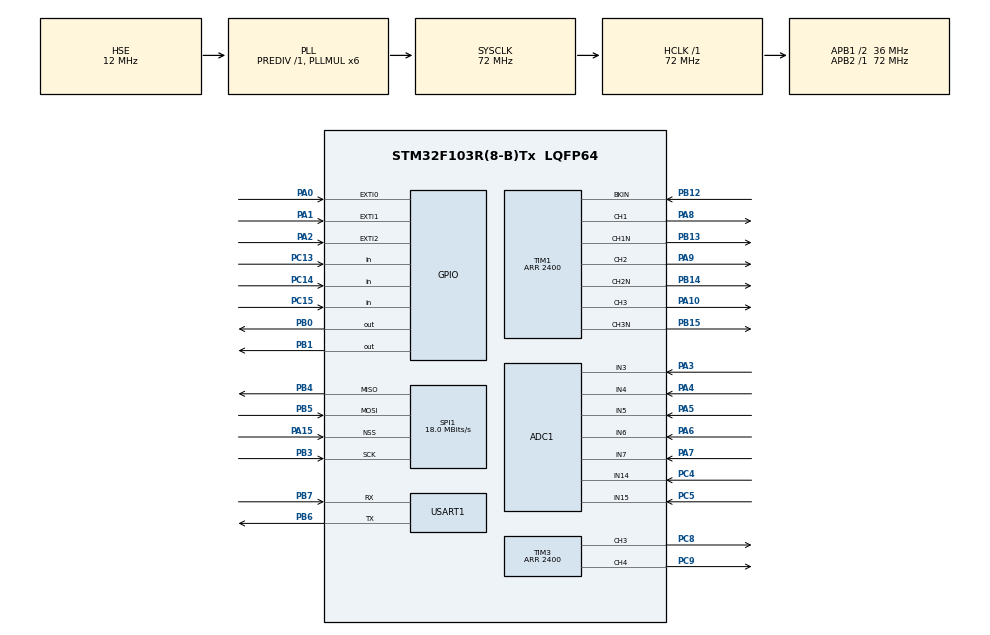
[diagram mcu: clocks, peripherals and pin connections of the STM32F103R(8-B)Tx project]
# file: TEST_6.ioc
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ADC1.Channel-0\#ChannelRegularConversion=ADC_CHANNEL_4
ADC1.Channel-1\#ChannelRegularConversion=ADC_CHANNEL_6
ADC1.Channel-2\#ChannelRegularConversion=ADC_CHANNEL_14
ADC1.ContinuousConvMode=ENABLE
ADC1.DataAlign=ADC_DATAALIGN_RIGHT
ADC1.DiscontinuousConvMode=DISABLE
ADC1.EnableAnalogWatchDog=false
ADC1.EnableRegularConversion=ENABLE
ADC1.ExternalTrigConvEdgeChoice=NONE
ADC1.InjNumberOfConversion=0
ADC1.NbrOfConversion=3
ADC1.NbrOfConversionFlag=1
ADC1.Rank-0\#ChannelRegularConversion=1
ADC1.Rank-1\#ChannelRegularConversion=2
ADC1.Rank-2\#ChannelRegularConversion=3
ADC1.SamplingTime-0\#ChannelRegularConversion=ADC_SAMPLETIME_28CYCLES_5
ADC1.SamplingTime-1\#ChannelRegularConversion=ADC_SAMPLETIME_28CYCLES_5
ADC1.SamplingTime-2\#ChannelRegularConversion=ADC_SAMPLETIME_28CYCLES_5
ADC1.ScanConvMode=ADC_SCAN_ENABLE
ADC1.master=1
Dma.ADC1.0.Direction=DMA_PERIPH_TO_MEMORY
Dma.ADC1.0.Instance=DMA1_Channel1
Dma.ADC1.0.MemDataAlignment=DMA_MDATAALIGN_HALFWORD
Dma.ADC1.0.MemInc=DMA_MINC_ENABLE
Dma.ADC1.0.Mode=DMA_CIRCULAR
Dma.ADC1.0.PeriphDataAlignment=DMA_PDATAALIGN_HALFWORD
Dma.ADC1.0.PeriphInc=DMA_PINC_DISABLE
Dma.ADC1.0.Priority=DMA_PRIORITY_VERY_HIGH
Dma.Request0=ADC1
Dma.Request1=SPI1_RX
Dma.SPI1_RX.1.Direction=DMA_PERIPH_TO_MEMORY
Dma.SPI1_RX.1.Instance=DMA1_Channel2
Dma.SPI1_RX.1.MemDataAlignment=DMA_MDATAALIGN_BYTE
Dma.SPI1_RX.1.MemInc=DMA_MINC_ENABLE
Dma.SPI1_RX.1.Mode=DMA_CIRCULAR
Dma.SPI1_RX.1.PeriphDataAlignment=DMA_PDATAALIGN_BYTE
Dma.SPI1_RX.1.PeriphInc=DMA_PINC_DISABLE
Dma.SPI1_RX.1.Priority=DMA_PRIORITY_LOW
Mcu.Family=STM32F1
Mcu.Name=STM32F103R(8-B)Tx
Mcu.Package=LQFP64
NVIC.DMA1_Channel1_IRQn=true\:4\:0\:true
NVIC.DMA1_Channel2_IRQn=true\:0\:0\:false
NVIC.EXTI0_IRQn=true\:1\:0\:true
NVIC.EXTI1_IRQn=true\:1\:0\:true
NVIC.EXTI2_IRQn=true\:1\:0\:true
NVIC.PriorityGroup=NVIC_PRIORITYGROUP_4
NVIC.SPI1_IRQn=true\:0\:0\:false
NVIC.TIM1_BRK_IRQn=true\:0\:0\:false
NVIC.TIM2_IRQn=true\:5\:0\:true
NVIC.TIM4_IRQn=true\:2\:0\:true
PA0-WKUP.GPIO_ModeDefaultEXTI=GPIO_MODE_IT_RISING_FALLING
PA0-WKUP.GPIO_PuPd=GPIO_NOPULL
PA0-WKUP.Signal=GPXTI0
PA1.GPIO_ModeDefaultEXTI=GPIO_MODE_IT_RISING_FALLING
PA1.GPIO_PuPd=GPIO_NOPULL
PA1.Signal=GPXTI1
PA10.Signal=S_TIM1_CH3
PA13.Mode=Serial_Wire
PA13.Signal=SYS_JTMS-SWDIO
PA14.Mode=Serial_Wire
PA14.Signal=SYS_JTCK-SWCLK
PA15.Mode=NSS_Signal_Hard_Input
PA15.Signal=SPI1_NSS
PA2.GPIO_ModeDefaultEXTI=GPIO_MODE_IT_RISING_FALLING
PA2.GPIO_PuPd=GPIO_NOPULL
PA2.Signal=GPXTI2
PA3.Signal=ADCx_IN3
PA4.Signal=ADCx_IN4
PA5.Signal=ADCx_IN5
PA6.Signal=ADCx_IN6
PA7.Signal=ADCx_IN7
PA8.Signal=S_TIM1_CH1
PA9.Signal=S_TIM1_CH2
PB0.Signal=GPIO_Output
PB1.GPIO_ModeDefaultOutputPP=GPIO_MODE_OUTPUT_PP
PB1.GPIO_Speed=GPIO_SPEED_HIGH
PB1.Signal=GPIO_Output
PB12.Mode=Activate-Break-Input
PB12.Signal=TIM1_BKIN
PB13.Mode=PWM Generation1 CH1 CH1N
PB13.Signal=TIM1_CH1N
PB14.Mode=PWM Generation2 CH2 CH2N
PB14.Signal=TIM1_CH2N
PB15.Mode=PWM Generation3 CH3 CH3N
PB15.Signal=TIM1_CH3N
PB3.Mode=Full_Duplex_Slave
PB3.Signal=SPI1_SCK
PB4.Mode=Full_Duplex_Slave
PB4.Signal=SPI1_MISO
PB5.Mode=Full_Duplex_Slave
PB5.Signal=SPI1_MOSI
PB6.Mode=Asynchronous
PB6.Signal=USART1_TX
PB7.Mode=Asynchronous
PB7.Signal=USART1_RX
PC13-TAMPER-RTC.GPIO_Mode=GPIO_MODE_INPUT
PC13-TAMPER-RTC.GPIO_PuPd=GPIO_PULLUP
PC13-TAMPER-RTC.Signal=GPIO_Input
PC14-OSC32_IN.GPIO_Mode=GPIO_MODE_INPUT
PC14-OSC32_IN.GPIO_PuPd=GPIO_PULLUP
PC14-OSC32_IN.Signal=GPIO_Input
PC15-OSC32_OUT.GPIO_Mode=GPIO_MODE_INPUT
PC15-OSC32_OUT.GPIO_PuPd=GPIO_PULLUP
PC15-OSC32_OUT.Signal=GPIO_Input
PC4.Signal=ADCx_IN14
PC5.Signal=ADCx_IN15
PC8.Signal=S_TIM3_CH3
PC9.Signal=S_TIM3_CH4
PD0-OSC_IN.Mode=HSE-External-Oscillator
PD0-OSC_IN.Signal=RCC_OSC_IN
PD1-OSC_OUT.Mode=HSE-External-Oscillator
PD1-OSC_OUT.Signal=RCC_OSC_OUT
ProjectManager.HeapSize=0x400
ProjectManager.StackSize=0x200
ProjectManager.TargetToolchain=SW4STM32
RCC.ADCPresc=RCC_ADCPCLK2_DIV6
RCC.AHBFreq_Value=72000000
RCC.APB1CLKDivider=RCC_HCLK_DIV2
RCC.APB1Freq_Value=36000000
RCC.APB1TimFreq_Value=72000000
RCC.APB2Freq_Value=72000000
RCC.APB2TimFreq_Value=72000000
RCC.HCLKFreq_Value=72000000
RCC.HSE_VALUE=12000000
RCC.HSIState=RCC_HSI_ON
RCC.PLLMUL=RCC_PLL_MUL6
RCC.PLLSourceVirtual=RCC_PLLSOURCE_HSE
RCC.SYSCLKFreq_VALUE=72000000
RCC.SYSCLKSource=RCC_SYSCLKSOURCE_PLLCLK
RCC.USBFreq_Value=72000000
SH.ADCx_IN14.0=ADC1_IN14,IN14
SH.ADCx_IN15.0=ADC1_IN15,IN15
SH.ADCx_IN3.0=ADC1_IN3,IN3
SH.ADCx_IN4.0=ADC1_IN4,IN4
SH.ADCx_IN5.0=ADC1_IN5,IN5
SH.ADCx_IN6.0=ADC1_IN6,IN6
SH.ADCx_IN7.0=ADC1_IN7,IN7
SH.S_TIM1_CH1.0=TIM1_CH1,PWM Generation1 CH1 CH1N
SH.S_TIM1_CH2.0=TIM1_CH2,PWM Generation2 CH2 CH2N
SH.S_TIM1_CH3.0=TIM1_CH3,PWM Generation3 CH3 CH3N
SH.S_TIM3_CH3.0=TIM3_CH3,PWM Generation3 CH3
SH.S_TIM3_CH4.0=TIM3_CH4,PWM Generation4 CH4
SPI1.BaudRatePrescaler=SPI_BAUDRATEPRESCALER_4
SPI1.CLKPhase=SPI_PHASE_2EDGE
SPI1.CalculateBaudRate=18.0 MBits/s
SPI1.VirtualNSS=VM_NSSHARD
SPI1.VirtualType=VM_SLAVE
TIM1.AutomaticOutput=TIM_AUTOMATICOUTPUT_DISABLE
TIM1.BreakPolarity=TIM_BREAKPOLARITY_LOW
TIM1.BreakState=TIM_BREAK_ENABLE
TIM1.Channel-PWM\ Generation2\ CH2\ CH2N=TIM_CHANNEL_2
TIM1.Channel-PWM\ Generation3\ CH3\ CH3N=TIM_CHANNEL_3
TIM1.CounterMode=TIM_COUNTERMODE_CENTERALIGNED3
TIM1.DeadTime=0
TIM1.OCFastMode_PWM-PWM\ Generation1\ CH1\ CH1N=TIM_OCFAST_ENABLE
TIM1.OCFastMode_PWM-PWM\ Generation2\ CH2\ CH2N=TIM_OCFAST_ENABLE
TIM1.OCFastMode_PWM-PWM\ Generation3\ CH3\ CH3N=TIM_OCFAST_ENABLE
TIM1.OCIdleState_1=TIM_OCIDLESTATE_SET
TIM1.OCIdleState_2=TIM_OCIDLESTATE_SET
TIM1.OCIdleState_3=TIM_OCIDLESTATE_SET
TIM1.OCNIdleState_1=TIM_OCNIDLESTATE_SET
TIM1.OCNIdleState_2=TIM_OCNIDLESTATE_SET
TIM1.OCNIdleState_3=TIM_OCNIDLESTATE_SET
TIM1.OCNPolarity_1=TIM_OCNPOLARITY_HIGH
TIM1.OCNPolarity_2=TIM_OCNPOLARITY_HIGH
TIM1.OCNPolarity_3=TIM_OCNPOLARITY_HIGH
TIM1.OCPolarity_1=TIM_OCPOLARITY_HIGH
TIM1.OCPolarity_2=TIM_OCPOLARITY_HIGH
TIM1.OCPolarity_3=TIM_OCPOLARITY_HIGH
TIM1.OffStateIDLEMode=TIM_OSSI_ENABLE
TIM1.OffStateRunMode=TIM_OSSR_ENABLE
TIM1.Period=2400
TIM2.Period=65535
TIM2.Prescaler=600
TIM3.Channel-PWM\ Generation3\ CH3=TIM_CHANNEL_3
TIM3.Channel-PWM\ Generation4\ CH4=TIM_CHANNEL_4
TIM3.OCFastMode_PWM-PWM\ Generation3\ CH3=TIM_OCFAST_ENABLE
TIM3.OCFastMode_PWM-PWM\ Generation4\ CH4=TIM_OCFAST_ENABLE
TIM3.Period=2400
TIM4.Period=4800
VP_TIM1_VS_ClockSourceINT.Mode=Internal
VP_TIM2_VS_ClockSourceINT.Mode=Internal
VP_TIM4_VS_ClockSourceINT.Mode=Internal
board=TEST_6

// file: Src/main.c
/**
  ******************************************************************************
  * File Name          : main.c
  * Description        : Main program body
  ******************************************************************************
  *
  * COPYRIGHT(c) 2016 STMicroelectronics
  *
  * Redistribution and use in source and binary forms, with or without modification,
  * are permitted provided that the following conditions are met:
  *   1. Redistributions of source code must retain the above copyright notice,
  *      this list of conditions and the following disclaimer.
  *   2. Redistributions in binary form must reproduce the above copyright notice,
  *      this list of conditions and the following disclaimer in the documentation
  *      and/or other materials provided with the distribution.
  *   3. Neither the name of STMicroelectronics nor the names of its contributors
  *      may be used to endorse or promote products derived from this software
  *      without specific prior written permission.
  *
  * THIS SOFTWARE IS PROVIDED BY THE COPYRIGHT HOLDERS AND CONTRIBUTORS "AS IS"
  * AND ANY EXPRESS OR IMPLIED WARRANTIES, INCLUDING, BUT NOT LIMITED TO, THE
  * IMPLIED WARRANTIES OF MERCHANTABILITY AND FITNESS FOR A PARTICULAR PURPOSE ARE
  * DISCLAIMED. IN NO EVENT SHALL THE COPYRIGHT HOLDER OR CONTRIBUTORS BE LIABLE
  * FOR ANY DIRECT, INDIRECT, INCIDENTAL, SPECIAL, EXEMPLARY, OR CONSEQUENTIAL
  * DAMAGES (INCLUDING, BUT NOT LIMITED TO, PROCUREMENT OF SUBSTITUTE GOODS OR
  * SERVICES; LOSS OF USE, DATA, OR PROFITS; OR BUSINESS INTERRUPTION) HOWEVER
  * CAUSED AND ON ANY THEORY OF LIABILITY, WHETHER IN CONTRACT, STRICT LIABILITY,
  * OR TORT (INCLUDING NEGLIGENCE OR OTHERWISE) ARISING IN ANY WAY OUT OF THE USE
  * OF THIS SOFTWARE, EVEN IF ADVISED OF THE POSSIBILITY OF SUCH DAMAGE.
  *
  ******************************************************************************
  */
#include "stm32f1xx_hal.h"
#include "adc.h"
#include "dma.h"
#include "spi.h"
#include "tim.h"
#include "usart.h"
#include "gpio.h"

/* USER CODE BEGIN Includes */
int32_t NO_OF;

uint16_t const SVM_TABLE[4800]={
	2078,2080,2081,2083,2084,2086,2087,2089,2090,2092,
	2093,2095,2097,2098,2100,2101,2103,2104,2106,2107,2109,2110,2112,2113,
	2115,2116,2118,2119,2121,2122,2123,2125,2126,2128,2129,2131,2132,
	2134,2135,2136,2138,2139,2141,2142,2144,2145,2146,2148,2149,2151,2152,
	2153,2155,2156,2158,2159,2160,2162,2163,2164,2166,2167,2168,2170,2171,
	2172,2174,2175,2176,2178,2179,2180,2182,2183,2184,2186,2187,2188,
	2189,2191,2192,2193,2195,2196,2197,2198,2200,2201,2202,2203,2205,2206,
	2207,2208,2210,2211,2212,2213,2214,2216,2217,2218,2219,2220,2222,
	2223,2224,2225,2226,2227,2229,2230,2231,2232,2233,2234,2236,2237,2238,
	2239,2240,2241,2242,2243,2245,2246,2247,2248,2249,2250,2251,2252,2253,
	2254,2255,2257,2258,2259,2260,2261,2262,2263,2264,2265,2266,2267,
	2268,2269,2270,2271,2272,2273,2274,2275,2276,2277,2278,2279,2280,2281,
	2282,2283,2284,2285,2286,2287,2288,2289,2290,2291,2292,2292,2293,
	2294,2295,2296,2297,2298,2299,2300,2301,2302,2302,2303,2304,2305,2306,
	2307,2308,2309,2309,2310,2311,2312,2313,2314,2314,2315,2316,2317,2318,
	2319,2319,2320,2321,2322,2323,2323,2324,2325,2326,2326,2327,2328,
	2329,2329,2330,2331,2332,2332,2333,2334,2335,2335,2336,2337,2338,2338,
	2339,2340,2340,2341,2342,2342,2343,2344,2344,2345,2346,2346,2347,
	2348,2348,2349,2350,2350,2351,2352,2352,2353,2353,2354,2355,2355,2356,
	2356,2357,2358,2358,2359,2359,2360,2360,2361,2362,2362,2363,2363,2364,
	2364,2365,2365,2366,2366,2367,2367,2368,2368,2369,2369,2370,2370,
	2371,2371,2372,2372,2373,2373,2374,2374,2375,2375,2376,2376,2376,2377,
	2377,2378,2378,2379,2379,2379,2380,2380,2381,2381,2381,2382,2382,
	2382,2383,2383,2384,2384,2384,2385,2385,2385,2386,2386,2386,2387,2387,
	2387,2388,2388,2388,2389,2389,2389,2389,2390,2390,2390,2391,2391,2391,
	2391,2392,2392,2392,2392,2393,2393,2393,2393,2394,2394,2394,2394,
	2394,2395,2395,2395,2395,2395,2396,2396,2396,2396,2396,2396,2397,2397,
	2397,2397,2397,2397,2397,2398,2398,2398,2398,2398,2398,2398,2398,
	2398,2399,2399,2399,2399,2399,2399,2399,2399,2399,2399,2399,2399,2399,
	2399,2399,2399,2399,2399,2399,2399,2399,2399,2399,2399,2399,2399,2399,
	2399,2399,2399,2399,2399,2399,2399,2399,2399,2399,2399,2399,2399,
	2399,2399,2399,2399,2399,2398,2398,2398,2398,2398,2398,2398,2398,2398,
	2397,2397,2397,2397,2397,2397,2397,2396,2396,2396,2396,2396,2396,
	2395,2395,2395,2395,2395,2394,2394,2394,2394,2394,2393,2393,2393,2393,
	2392,2392,2392,2392,2391,2391,2391,2391,2390,2390,2390,2389,2389,2389,
	2389,2388,2388,2388,2387,2387,2387,2386,2386,2386,2385,2385,2385,
	2384,2384,2384,2383,2383,2382,2382,2382,2381,2381,2381,2380,2380,2379,
	2379,2379,2378,2378,2377,2377,2376,2376,2376,2375,2375,2374,2374,
	2373,2373,2372,2372,2371,2371,2370,2370,2369,2369,2368,2368,2367,2367,
	2366,2366,2365,2365,2364,2364,2363,2363,2362,2362,2361,2360,2360,2359,
	2359,2358,2358,2357,2356,2356,2355,2355,2354,2353,2353,2352,2352,
	2351,2350,2350,2349,2348,2348,2347,2346,2346,2345,2344,2344,2343,2342,
	2342,2341,2340,2340,2339,2338,2338,2337,2336,2335,2335,2334,2333,
	2332,2332,2331,2330,2329,2329,2328,2327,2326,2326,2325,2324,2323,2323,
	2322,2321,2320,2319,2319,2318,2317,2316,2315,2314,2314,2313,2312,2311,
	2310,2309,2309,2308,2307,2306,2305,2304,2303,2302,2302,2301,2300,
	2299,2298,2297,2296,2295,2294,2293,2292,2292,2291,2290,2289,2288,2287,
	2286,2285,2284,2283,2282,2281,2280,2279,2278,2277,2276,2275,2274,
	2273,2272,2271,2270,2269,2268,2267,2266,2265,2264,2263,2262,2261,2260,
	2259,2258,2257,2255,2254,2253,2252,2251,2250,2249,2248,2247,2246,2245,
	2243,2242,2241,2240,2239,2238,2237,2236,2234,2233,2232,2231,2230,
	2229,2227,2226,2225,2224,2223,2222,2220,2219,2218,2217,2216,2214,2213,
	2212,2211,2210,2208,2207,2206,2205,2203,2202,2201,2200,2198,2197,
	2196,2195,2193,2192,2191,2189,2188,2187,2186,2184,2183,2182,2180,2179,
	2178,2176,2175,2174,2172,2171,2170,2168,2167,2166,2164,2163,2162,2160,
	2159,2158,2156,2155,2153,2152,2151,2149,2148,2146,2145,2144,2142,
	2141,2139,2138,2136,2135,2134,2132,2131,2129,2128,2126,2125,2123,2122,
	2121,2119,2118,2116,2115,2113,2112,2110,2109,2107,2106,2104,2103,
	2101,2100,2098,2097,2095,2093,2092,2090,2089,2087,2086,2084,2083,2081,
	2080,2078,2076,2075,2073,2072,2070,2068,2067,2065,2064,2062,2060,2059,
	2057,2056,2054,2052,2051,2049,2047,2046,2044,2043,2041,2039,2038,
	2036,2034,2033,2031,2029,2028,2026,2024,2023,2021,2019,2017,2016,2014,
	2012,2011,2009,2007,2005,2004,2002,2000,1999,1997,1995,1993,1992,
	1990,1988,1986,1984,1983,1981,1979,1977,1976,1974,1972,1970,1968,1967,
	1965,1963,1961,1959,1958,1956,1954,1952,1950,1949,1947,1945,1943,1941,
	1939,1937,1936,1934,1932,1930,1928,1926,1924,1923,1921,1919,1917,
	1915,1913,1911,1909,1907,1905,1904,1902,1900,1898,1896,1894,1892,1890,
	1888,1886,1884,1882,1880,1878,1876,1874,1873,1871,1869,1867,1865,
	1863,1861,1859,1857,1855,1853,1851,1849,1847,1845,1843,1841,1839,1837,
	1835,1833,1831,1829,1827,1824,1822,1820,1818,1816,1814,1812,1810,1808,
	1806,1804,1802,1800,1798,1796,1794,1791,1789,1787,1785,1783,1781,
	1779,1777,1775,1772,1770,1768,1766,1764,1762,1760,1758,1755,1753,1751,
	1749,1747,1745,1743,1740,1738,1736,1734,1732,1730,1727,1725,1723,
	1721,1719,1716,1714,1712,1710,1708,1705,1703,1701,1699,1697,1694,1692,
	1690,1688,1685,1683,1681,1679,1676,1674,1672,1670,1667,1665,1663,1661,
	1658,1656,1654,1652,1649,1647,1645,1642,1640,1638,1636,1633,1631,
	1629,1626,1624,1622,1619,1617,1615,1612,1610,1608,1605,1603,1601,1598,
	1596,1594,1591,1589,1587,1584,1582,1580,1577,1575,1572,1570,1568,
	1565,1563,1561,1558,1556,1553,1551,1549,1546,1544,1541,1539,1537,1534,
	1532,1529,1527,1524,1522,1520,1517,1515,1512,1510,1507,1505,1503,1500,
	1498,1495,1493,1490,1488,1485,1483,1480,1478,1475,1473,1470,1468,
	1466,1463,1461,1458,1456,1453,1451,1448,1446,1443,1441,1438,1435,1433,
	1430,1428,1425,1423,1420,1418,1415,1413,1410,1408,1405,1403,1400,
	1397,1395,1392,1390,1387,1385,1382,1380,1377,1374,1372,1369,1367,1364,
	1361,1359,1356,1354,1351,1349,1346,1343,1341,1338,1335,1333,1330,1328,
	1325,1322,1320,1317,1315,1312,1309,1307,1304,1301,1299,1296,1293,
	1291,1288,1285,1283,1280,1278,1275,1272,1270,1267,1264,1262,1259,1256,
	1253,1251,1248,1245,1243,1240,1237,1235,1232,1229,1227,1224,1221,
	1218,1216,1213,1210,1208,1205,1202,1199,1197,1194,1191,1189,1186,1183,
	1180,1178,1175,1172,1169,1167,1164,1161,1158,1156,1153,1150,1147,1145,
	1142,1139,1136,1134,1131,1128,1125,1123,1120,1117,1114,1111,1109,
	1106,1103,1100,1097,1095,1092,1089,1086,1083,1081,1078,1075,1072,1069,
	1067,1064,1061,1058,1055,1053,1050,1047,1044,1041,1038,1036,1033,
	1030,1027,1024,1021,1019,1016,1013,1010,1007,1004,1001,999,996,993,990,
	987,984,981,979,976,973,970,967,964,961,958,956,953,950,947,944,941,
	938,935,932,930,927,924,921,918,915,912,909,906,903,900,898,895,892,
	889,886,883,880,877,874,871,868,865,863,860,857,854,851,848,845,842,
	839,836,833,830,827,824,821,818,815,812,810,807,804,801,798,795,792,
	789,786,783,780,777,774,771,768,765,762,759,756,753,750,747,744,741,
	738,735,732,729,726,723,720,717,714,711,708,705,702,699,696,693,690,
	687,684,681,678,675,672,669,666,663,660,657,654,651,648,645,642,639,
	636,633,630,627,624,621,618,615,612,609,605,602,599,596,593,590,587,
	584,581,578,575,572,569,566,563,560,557,554,551,548,544,541,538,535,
	532,529,526,523,520,517,514,511,508,505,502,498,495,492,489,486,483,
	480,477,474,471,468,465,462,458,455,452,449,446,443,440,437,434,431,
	428,425,421,418,415,412,409,406,403,400,397,394,390,387,384,381,378,
	375,372,369,366,363,359,356,353,350,347,344,341,338,335,331,328,325,
	322,319,316,313,310,307,303,300,297,294,291,288,285,282,278,275,272,
	269,266,263,260,257,253,250,247,244,241,238,235,232,228,225,222,219,
	216,213,210,207,203,200,197,194,191,188,185,182,178,175,172,169,166,
	163,160,156,153,150,147,144,141,138,135,131,128,125,122,119,116,113,
	109,106,103,100,97,94,91,87,84,81,78,75,72,69,65,62,59,56,53,50,47,
	43,40,37,34,31,28,25,21,18,15,12,9,6,3,0,0,0,0,0,0,0,0,0,0,0,0,0,0,
	0,0,0,0,0,0,0,0,0,0,0,0,0,0,0,0,0,0,0,0,0,0,0,0,0,0,0,0,0,0,0,0,0,0,
	0,0,0,0,0,0,0,0,0,0,0,0,0,0,0,0,0,0,0,0,0,0,0,0,0,0,0,0,0,0,0,0,0,0,
	0,0,0,0,0,0,0,0,0,0,0,0,0,0,0,0,0,0,0,0,0,0,0,0,0,0,0,0,0,0,0,0,0,0,
	0,0,0,0,0,0,0,0,0,0,0,0,0,0,0,0,0,0,0,0,0,0,0,0,0,0,0,0,0,0,0,0,0,0,
	0,0,0,0,0,0,0,0,0,0,0,0,0,0,0,0,0,0,0,0,0,0,0,0,0,0,0,0,0,0,0,0,0,0,
	0,0,0,0,0,0,0,0,0,0,0,0,0,0,0,0,0,0,0,0,0,0,0,0,0,0,0,0,0,0,0,0,0,0,
	0,0,0,0,0,0,0,0,0,0,0,0,0,0,0,0,0,0,0,0,0,0,0,0,0,0,0,0,0,0,0,0,0,0,
	0,0,0,0,0,0,0,0,0,0,0,0,0,0,0,0,0,0,0,0,0,0,0,0,0,0,0,0,0,0,0,0,0,0,
	0,0,0,0,0,0,0,0,0,0,0,0,0,0,0,0,0,0,0,0,0,0,0,0,0,0,0,0,0,0,0,0,0,0,
	0,0,0,0,0,0,0,0,0,0,0,0,0,0,0,0,0,0,0,0,0,0,0,0,0,0,0,0,0,0,0,0,0,0,
	0,0,0,0,0,0,0,0,0,0,0,0,0,0,0,0,0,0,0,0,0,0,0,0,0,0,0,0,0,0,0,0,0,0,
	0,0,0,0,0,0,0,0,0,0,0,0,0,0,0,0,0,0,0,0,0,0,0,0,0,0,0,0,0,0,0,0,0,0,
	0,0,0,0,0,0,0,0,0,0,0,0,0,0,0,0,0,0,0,0,0,0,0,0,0,0,0,0,0,0,0,0,0,0,
	0,0,0,0,0,0,0,0,0,0,0,0,0,0,0,0,0,0,0,0,0,0,0,0,0,0,0,0,0,0,0,0,0,0,
	0,0,0,0,0,0,0,0,0,0,0,0,0,0,0,0,0,0,0,0,0,0,0,0,0,0,0,0,0,0,0,0,0,0,
	0,0,0,0,0,0,0,0,0,0,0,0,0,0,0,0,0,0,0,0,0,0,0,0,0,0,0,0,0,0,0,0,0,0,
	0,0,0,0,0,0,0,0,0,0,0,0,0,0,0,0,0,0,0,0,0,0,0,0,0,0,0,0,0,0,0,0,0,0,
	0,0,0,0,0,0,0,0,0,0,0,0,0,0,0,0,0,0,0,0,0,0,0,0,0,0,0,0,0,0,0,0,0,0,
	0,0,0,0,0,0,0,0,0,0,0,0,0,0,0,0,0,0,0,0,0,0,0,0,0,0,0,0,0,0,0,0,0,0,
	0,0,0,0,0,0,0,0,0,0,0,0,0,0,0,0,0,0,0,0,0,0,0,0,0,0,0,0,0,0,0,0,0,0,
	0,0,0,0,0,0,0,0,0,0,0,0,0,0,0,0,0,0,0,0,0,0,0,0,0,0,0,0,0,0,0,0,0,0,
	0,0,0,0,0,0,0,0,0,0,0,0,0,0,0,0,0,0,0,0,0,0,0,0,0,0,0,0,0,0,0,0,0,0,
	0,0,0,0,0,0,0,0,0,0,0,0,0,0,0,0,0,0,0,0,0,0,0,0,0,0,0,0,0,0,0,0,0,0,
	0,0,0,0,0,0,0,0,0,0,0,0,0,0,0,0,0,0,0,0,0,0,0,0,0,0,0,0,0,0,0,0,0,0,
	0,0,0,0,0,0,0,0,0,0,0,0,0,0,0,0,0,0,0,0,0,0,0,0,0,0,0,0,0,0,0,0,0,0,
	0,0,0,0,0,0,0,0,0,0,0,0,0,0,0,0,0,0,0,0,0,0,0,0,0,0,0,0,0,0,0,0,0,0,
	0,0,0,0,0,0,0,0,0,0,0,0,0,0,0,0,0,0,0,0,0,0,0,0,0,0,0,0,0,0,0,0,0,0,
	0,0,0,0,0,0,0,0,0,0,0,0,0,0,0,0,0,0,0,0,0,0,0,0,0,0,0,0,0,0,0,0,0,0,
	0,0,0,0,0,0,0,0,0,0,0,0,0,0,0,0,0,0,0,0,0,0,0,0,0,0,0,0,0,0,0,0,0,0,
	0,0,0,0,0,0,0,0,0,0,0,0,0,0,0,0,0,0,0,0,0,0,0,0,0,0,0,0,0,0,0,0,0,0,
	0,0,0,0,0,0,0,0,0,0,0,0,0,0,0,0,0,0,0,0,0,0,0,0,0,0,0,0,0,0,0,0,0,0,
	0,0,0,0,0,0,0,0,0,0,0,0,0,0,0,0,0,0,0,0,0,0,0,0,0,0,0,0,0,0,0,0,0,0,
	0,0,0,0,0,0,0,0,0,0,0,0,0,0,0,0,0,0,0,0,0,0,0,0,0,0,0,0,0,0,0,0,0,0,
	0,0,0,0,0,0,0,0,0,0,0,0,0,0,0,0,0,0,0,0,0,0,0,0,0,0,0,0,0,0,0,0,0,0,
	0,0,0,0,0,0,0,0,0,0,0,0,0,0,0,0,0,0,0,0,0,0,0,0,0,0,0,0,0,0,0,0,0,0,
	0,0,0,0,0,0,0,0,0,0,0,0,0,0,0,0,0,0,0,0,0,0,0,0,0,0,0,0,0,0,0,0,0,0,
	0,0,0,0,0,0,0,0,0,0,0,0,0,0,0,0,0,0,0,0,0,0,0,0,0,0,0,0,0,0,0,0,0,0,
	0,0,0,0,0,0,0,0,0,0,0,0,0,0,0,0,0,0,0,0,0,0,0,0,0,0,0,0,0,0,0,0,0,0,
	0,0,0,0,0,0,0,0,0,0,0,0,0,0,0,0,0,0,0,0,0,0,0,0,0,0,0,0,0,0,0,0,0,0,
	0,0,0,0,0,0,0,0,0,0,0,0,0,0,0,0,0,0,0,0,0,0,0,0,0,0,0,0,0,0,0,0,0,0,
	0,0,0,0,0,0,0,0,0,0,0,0,0,0,0,0,0,0,0,0,0,0,0,0,0,0,0,0,0,0,0,0,0,0,
	0,0,0,0,0,0,0,0,0,0,0,0,0,0,0,0,0,0,0,0,0,0,0,0,0,0,0,0,0,0,0,0,0,0,
	0,0,0,0,0,0,0,0,0,0,0,0,0,0,0,0,0,0,0,0,0,0,0,0,0,0,0,0,0,0,0,0,0,0,
	0,0,0,0,0,0,0,0,0,0,0,0,0,0,0,0,0,0,0,0,0,0,0,0,0,0,0,0,0,0,0,0,0,0,
	0,0,0,0,0,0,0,0,0,0,0,0,0,0,0,0,0,0,0,0,0,0,0,0,0,0,0,0,0,0,0,0,0,0,
	0,0,0,0,0,0,0,0,0,0,0,0,0,0,0,0,0,0,0,0,0,0,0,0,0,0,0,0,0,0,0,0,0,0,
	0,0,0,0,0,0,0,0,0,0,0,0,0,0,0,0,0,0,0,0,0,0,0,3,6,9,12,15,18,21,25,
	28,31,34,37,40,43,47,50,53,56,59,62,65,69,72,75,78,81,84,87,91,94,97,
	100,103,106,109,113,116,119,122,125,128,131,135,138,141,144,147,150,
	153,156,160,163,166,169,172,175,178,182,185,188,191,194,197,200,203,
	207,210,213,216,219,222,225,228,232,235,238,241,244,247,250,253,257,
	260,263,266,269,272,275,278,282,285,288,291,294,297,300,303,307,310,
	313,316,319,322,325,328,331,335,338,341,344,347,350,353,356,359,363,
	366,369,372,375,378,381,384,387,390,394,397,400,403,406,409,412,415,
	418,421,425,428,431,434,437,440,443,446,449,452,455,458,462,465,468,
	471,474,477,480,483,486,489,492,495,498,502,505,508,511,514,517,520,
	523,526,529,532,535,538,541,544,548,551,554,557,560,563,566,569,572,
	575,578,581,584,587,590,593,596,599,602,605,609,612,615,618,621,624,
	627,630,633,636,639,642,645,648,651,654,657,660,663,666,669,672,675,
	678,681,684,687,690,693,696,699,702,705,708,711,714,717,720,723,726,
	729,732,735,738,741,744,747,750,753,756,759,762,765,768,771,774,777,
	780,783,786,789,792,795,798,801,804,807,810,812,815,818,821,824,827,
	830,833,836,839,842,845,848,851,854,857,860,863,865,868,871,874,877,
	880,883,886,889,892,895,898,900,903,906,909,912,915,918,921,924,927,
	930,932,935,938,941,944,947,950,953,956,958,961,964,967,970,973,976,
	979,981,984,987,990,993,996,999,1001,1004,1007,1010,1013,1016,1019,
	1021,1024,1027,1030,1033,1036,1038,1041,1044,1047,1050,1053,1055,1058,
	1061,1064,1067,1069,1072,1075,1078,1081,1083,1086,1089,1092,1095,1097,
	1100,1103,1106,1109,1111,1114,1117,1120,1123,1125,1128,1131,1134,
	1136,1139,1142,1145,1147,1150,1153,1156,1158,1161,1164,1167,1169,1172,
	1175,1178,1180,1183,1186,1189,1191,1194,1197,1200,1202,1205,1208,
	1210,1213,1216,1218,1221,1224,1227,1229,1232,1235,1237,1240,1243,1245,
	1248,1251,1253,1256,1259,1262,1264,1267,1270,1272,1275,1278,1280,1283,
	1285,1288,1291,1293,1296,1299,1301,1304,1307,1309,1312,1315,1317,
	1320,1322,1325,1328,1330,1333,1335,1338,1341,1343,1346,1349,1351,1354,
	1356,1359,1361,1364,1367,1369,1372,1374,1377,1380,1382,1385,1387,
	1390,1392,1395,1397,1400,1403,1405,1408,1410,1413,1415,1418,1420,1423,
	1425,1428,1430,1433,1435,1438,1441,1443,1446,1448,1451,1453,1456,1458,
	1461,1463,1466,1468,1470,1473,1475,1478,1480,1483,1485,1488,1490,
	1493,1495,1498,1500,1503,1505,1507,1510,1512,1515,1517,1520,1522,1524,
	1527,1529,1532,1534,1537,1539,1541,1544,1546,1549,1551,1553,1556,
	1558,1561,1563,1565,1568,1570,1572,1575,1577,1580,1582,1584,1587,1589,
	1591,1594,1596,1598,1601,1603,1605,1608,1610,1612,1615,1617,1619,1622,
	1624,1626,1629,1631,1633,1636,1638,1640,1642,1645,1647,1649,1652,
	1654,1656,1658,1661,1663,1665,1667,1670,1672,1674,1676,1679,1681,1683,
	1685,1688,1690,1692,1694,1697,1699,1701,1703,1705,1708,1710,1712,
	1714,1716,1719,1721,1723,1725,1727,1730,1732,1734,1736,1738,1740,1743,
	1745,1747,1749,1751,1753,1755,1758,1760,1762,1764,1766,1768,1770,1772,
	1775,1777,1779,1781,1783,1785,1787,1789,1791,1794,1796,1798,1800,
	1802,1804,1806,1808,1810,1812,1814,1816,1818,1820,1822,1824,1827,1829,
	1831,1833,1835,1837,1839,1841,1843,1845,1847,1849,1851,1853,1855,
	1857,1859,1861,1863,1865,1867,1869,1871,1873,1874,1876,1878,1880,1882,
	1884,1886,1888,1890,1892,1894,1896,1898,1900,1902,1904,1905,1907,1909,
	1911,1913,1915,1917,1919,1921,1923,1924,1926,1928,1930,1932,1934,
	1936,1937,1939,1941,1943,1945,1947,1949,1950,1952,1954,1956,1958,1959,
	1961,1963,1965,1967,1968,1970,1972,1974,1976,1977,1979,1981,1983,
	1984,1986,1988,1990,1992,1993,1995,1997,1999,2000,2002,2004,2005,2007,
	2009,2011,2012,2014,2016,2017,2019,2021,2023,2024,2026,2028,2029,2031,
	2033,2034,2036,2038,2039,2041,2043,2044,2046,2047,2049,2051,2052,
	2054,2056,2057,2059,2060,2062,2064,2065,2067,2068,2070,2072,2073,2075,
	2076,2078,2080,2081,2083,2084,2086,2087,2089,2090,2092,2093,2095,
	2097,2098,2100,2101,2103,2104,2106,2107,2109,2110,2112,2113,2115,2116,
	2118,2119,2121,2122,2123,2125,2126,2128,2129,2131,2132,2134,2135,2136,
	2138,2139,2141,2142,2144,2145,2146,2148,2149,2151,2152,2153,2155,
	2156,2158,2159,2160,2162,2163,2164,2166,2167,2168,2170,2171,2172,2174,
	2175,2176,2178,2179,2180,2182,2183,2184,2186,2187,2188,2189,2191,
	2192,2193,2195,2196,2197,2198,2200,2201,2202,2203,2205,2206,2207,2208,
	2210,2211,2212,2213,2214,2216,2217,2218,2219,2220,2222,2223,2224,2225,
	2226,2227,2229,2230,2231,2232,2233,2234,2236,2237,2238,2239,2240,
	2241,2242,2243,2245,2246,2247,2248,2249,2250,2251,2252,2253,2254,2255,
	2257,2258,2259,2260,2261,2262,2263,2264,2265,2266,2267,2268,2269,
	2270,2271,2272,2273,2274,2275,2276,2277,2278,2279,2280,2281,2282,2283,
	2284,2285,2286,2287,2288,2289,2290,2291,2292,2292,2293,2294,2295,2296,
	2297,2298,2299,2300,2301,2302,2302,2303,2304,2305,2306,2307,2308,
	2309,2309,2310,2311,2312,2313,2314,2314,2315,2316,2317,2318,2319,2319,
	2320,2321,2322,2323,2323,2324,2325,2326,2326,2327,2328,2329,2329,
	2330,2331,2332,2332,2333,2334,2335,2335,2336,2337,2338,2338,2339,2340,
	2340,2341,2342,2342,2343,2344,2344,2345,2346,2346,2347,2348,2348,2349,
	2350,2350,2351,2352,2352,2353,2353,2354,2355,2355,2356,2356,2357,
	2358,2358,2359,2359,2360,2360,2361,2362,2362,2363,2363,2364,2364,2365,
	2365,2366,2366,2367,2367,2368,2368,2369,2369,2370,2370,2371,2371,
	2372,2372,2373,2373,2374,2374,2375,2375,2376,2376,2376,2377,2377,2378,
	2378,2379,2379,2379,2380,2380,2381,2381,2381,2382,2382,2382,2383,2383,
	2384,2384,2384,2385,2385,2385,2386,2386,2386,2387,2387,2387,2388,
	2388,2388,2389,2389,2389,2389,2390,2390,2390,2391,2391,2391,2391,2392,
	2392,2392,2392,2393,2393,2393,2393,2394,2394,2394,2394,2394,2395,
	2395,2395,2395,2395,2396,2396,2396,2396,2396,2396,2397,2397,2397,2397,
	2397,2397,2397,2398,2398,2398,2398,2398,2398,2398,2398,2398,2399,2399,
	2399,2399,2399,2399,2399,2399,2399,2399,2399,2399,2399,2399,2399,
	2399,2399,2399,2399,2399,2399,2399,2399,2399,2399,2399,2399,2399,2399,
	2399,2399,2399,2399,2399,2399,2399,2399,2399,2399,2399,2399,2399,
	2399,2399,2399,2398,2398,2398,2398,2398,2398,2398,2398,2398,2397,2397,
	2397,2397,2397,2397,2397,2396,2396,2396,2396,2396,2396,2395,2395,2395,
	2395,2395,2394,2394,2394,2394,2394,2393,2393,2393,2393,2392,2392,
	2392,2392,2391,2391,2391,2391,2390,2390,2390,2389,2389,2389,2389,2388,
	2388,2388,2387,2387,2387,2386,2386,2386,2385,2385,2385,2384,2384,
	2384,2383,2383,2382,2382,2382,2381,2381,2381,2380,2380,2379,2379,2379,
	2378,2378,2377,2377,2376,2376,2376,2375,2375,2374,2374,2373,2373,2372,
	2372,2371,2371,2370,2370,2369,2369,2368,2368,2367,2367,2366,2366,
	2365,2365,2364,2364,2363,2363,2362,2362,2361,2360,2360,2359,2359,2358,
	2358,2357,2356,2356,2355,2355,2354,2353,2353,2352,2352,2351,2350,
	2350,2349,2348,2348,2347,2346,2346,2345,2344,2344,2343,2342,2342,2341,
	2340,2340,2339,2338,2338,2337,2336,2335,2335,2334,2333,2332,2332,2331,
	2330,2329,2329,2328,2327,2326,2326,2325,2324,2323,2323,2322,2321,
	2320,2319,2319,2318,2317,2316,2315,2314,2314,2313,2312,2311,2310,2309,
	2309,2308,2307,2306,2305,2304,2303,2302,2302,2301,2300,2299,2298,
	2297,2296,2295,2294,2293,2292,2292,2291,2290,2289,2288,2287,2286,2285,
	2284,2283,2282,2281,2280,2279,2278,2277,2276,2275,2274,2273,2272,2271,
	2270,2269,2268,2267,2266,2265,2264,2263,2262,2261,2260,2259,2258,
	2257,2255,2254,2253,2252,2251,2250,2249,2248,2247,2246,2245,2243,2242,
	2241,2240,2239,2238,2237,2236,2234,2233,2232,2231,2230,2229,2227,
	2226,2225,2224,2223,2222,2220,2219,2218,2217,2216,2214,2213,2212,2211,
	2210,2208,2207,2206,2205,2203,2202,2201,2200,2198,2197,2196,2195,2193,
	2192,2191,2189,2188,2187,2186,2184,2183,2182,2180,2179,2178,2176,
	2175,2174,2172,2171,2170,2168,2167,2166,2164,2163,2162,2160,2159,2158,
	2156,2155,2153,2152,2151,2149,2148,2146,2145,2144,2142,2141,2139,
	2138,2136,2135,2134,2132,2131,2129,2128,2126,2125,2123,2122,2121,2119,
	2118,2116,2115,2113,2112,2110,2109,2107,2106,2104,2103,2101,2100,2098,
	2097,2095,2093,2092,2090,2089,2087,2086,2084,2083,2081,2080,
	};

int16_t const COSINE_TABLE[4800]={
2047,2047,2047,2047,2047,2047,2047,2047,2047,2047,
	2047,2047,2047,2047,2047,2047,2047,2047,2047,2047,2047,2047,2047,
	2047,2046,2046,2046,2046,2046,2046,2046,2046,2046,2046,2045,2045,2045,
	2045,2045,2045,2045,2045,2044,2044,2044,2044,2044,2044,2043,2043,
	2043,2043,2043,2043,2042,2042,2042,2042,2042,2041,2041,2041,2041,2041,
	2040,2040,2040,2040,2039,2039,2039,2039,2038,2038,2038,2038,2037,2037,
	2037,2037,2036,2036,2036,2035,2035,2035,2035,2034,2034,2034,2033,
	2033,2033,2032,2032,2032,2031,2031,2031,2030,2030,2030,2029,2029,2029,
	2028,2028,2027,2027,2027,2026,2026,2026,2025,2025,2024,2024,2024,
	2023,2023,2022,2022,2021,2021,2021,2020,2020,2019,2019,2018,2018,2017,
	2017,2017,2016,2016,2015,2015,2014,2014,2013,2013,2012,2012,2011,2011,
	2010,2010,2009,2009,2008,2008,2007,2007,2006,2005,2005,2004,2004,
	2003,2003,2002,2002,2001,2000,2000,1999,1999,1998,1998,1997,1996,1996,
	1995,1995,1994,1993,1993,1992,1992,1991,1990,1990,1989,1988,1988,
	1987,1986,1986,1985,1984,1984,1983,1982,1982,1981,1980,1980,1979,1978,
	1978,1977,1976,1976,1975,1974,1973,1973,1972,1971,1971,1970,1969,1968,
	1968,1967,1966,1965,1965,1964,1963,1962,1962,1961,1960,1959,1959,
	1958,1957,1956,1955,1955,1954,1953,1952,1951,1951,1950,1949,1948,1947,
	1946,1946,1945,1944,1943,1942,1941,1941,1940,1939,1938,1937,1936,
	1935,1934,1934,1933,1932,1931,1930,1929,1928,1927,1926,1926,1925,1924,
	1923,1922,1921,1920,1919,1918,1917,1916,1915,1914,1913,1912,1911,1911,
	1910,1909,1908,1907,1906,1905,1904,1903,1902,1901,1900,1899,1898,
	1897,1896,1895,1894,1893,1892,1891,1890,1889,1887,1886,1885,1884,1883,
	1882,1881,1880,1879,1878,1877,1876,1875,1874,1873,1872,1870,1869,
	1868,1867,1866,1865,1864,1863,1862,1860,1859,1858,1857,1856,1855,1854,
	1853,1851,1850,1849,1848,1847,1846,1845,1843,1842,1841,1840,1839,1837,
	1836,1835,1834,1833,1832,1830,1829,1828,1827,1825,1824,1823,1822,
	1821,1819,1818,1817,1816,1814,1813,1812,1811,1809,1808,1807,1806,1804,
	1803,1802,1801,1799,1798,1797,1795,1794,1793,1792,1790,1789,1788,
	1786,1785,1784,1782,1781,1780,1778,1777,1776,1774,1773,1772,1770,1769,
	1768,1766,1765,1764,1762,1761,1760,1758,1757,1755,1754,1753,1751,1750,
	1749,1747,1746,1744,1743,1741,1740,1739,1737,1736,1734,1733,1732,
	1730,1729,1727,1726,1724,1723,1721,1720,1719,1717,1716,1714,1713,1711,
	1710,1708,1707,1705,1704,1702,1701,1699,1698,1696,1695,1693,1692,
	1690,1689,1687,1686,1684,1683,1681,1680,1678,1677,1675,1674,1672,1670,
	1669,1667,1666,1664,1663,1661,1660,1658,1656,1655,1653,1652,1650,1648,
	1647,1645,1644,1642,1640,1639,1637,1636,1634,1632,1631,1629,1628,
	1626,1624,1623,1621,1619,1618,1616,1614,1613,1611,1609,1608,1606,1605,
	1603,1601,1599,1598,1596,1594,1593,1591,1589,1588,1586,1584,1583,
	1581,1579,1578,1576,1574,1572,1571,1569,1567,1565,1564,1562,1560,1559,
	1557,1555,1553,1552,1550,1548,1546,1545,1543,1541,1539,1537,1536,1534,
	1532,1530,1529,1527,1525,1523,1521,1520,1518,1516,1514,1512,1511,
	1509,1507,1505,1503,1502,1500,1498,1496,1494,1492,1491,1489,1487,1485,
	1483,1481,1480,1478,1476,1474,1472,1470,1468,1466,1465,1463,1461,
	1459,1457,1455,1453,1451,1450,1448,1446,1444,1442,1440,1438,1436,1434,
	1432,1430,1429,1427,1425,1423,1421,1419,1417,1415,1413,1411,1409,1407,
	1405,1403,1401,1399,1398,1396,1394,1392,1390,1388,1386,1384,1382,
	1380,1378,1376,1374,1372,1370,1368,1366,1364,1362,1360,1358,1356,1354,
	1352,1350,1348,1346,1344,1342,1340,1338,1336,1334,1332,1330,1328,
	1325,1323,1321,1319,1317,1315,1313,1311,1309,1307,1305,1303,1301,1299,
	1297,1295,1293,1290,1288,1286,1284,1282,1280,1278,1276,1274,1272,1270,
	1267,1265,1263,1261,1259,1257,1255,1253,1250,1248,1246,1244,1242,
	1240,1238,1236,1233,1231,1229,1227,1225,1223,1221,1218,1216,1214,1212,
	1210,1208,1205,1203,1201,1199,1197,1195,1192,1190,1188,1186,1184,
	1181,1179,1177,1175,1173,1171,1168,1166,1164,1162,1159,1157,1155,1153,
	1151,1148,1146,1144,1142,1140,1137,1135,1133,1131,1128,1126,1124,1122,
	1119,1117,1115,1113,1110,1108,1106,1104,1101,1099,1097,1095,1092,
	1090,1088,1086,1083,1081,1079,1076,1074,1072,1070,1067,1065,1063,1060,
	1058,1056,1054,1051,1049,1047,1044,1042,1040,1037,1035,1033,1030,
	1028,1026,1023,1021,1019,1017,1014,1012,1010,1007,1005,1003,1000,998,
	996,993,991,988,986,984,981,979,977,974,972,970,967,965,963,960,958,
	955,953,951,948,946,944,941,939,936,934,932,929,927,924,922,920,917,
	915,913,910,908,905,903,900,898,896,893,891,888,886,884,881,879,876,
	874,871,869,867,864,862,859,857,854,852,850,847,845,842,840,837,835,
	832,830,828,825,823,820,818,815,813,810,808,805,803,801,798,796,793,
	791,788,786,783,781,778,776,773,771,768,766,763,761,758,756,753,751,
	748,746,743,741,738,736,733,731,728,726,723,721,718,716,713,711,708,
	706,703,701,698,696,693,691,688,686,683,681,678,676,673,670,668,665,
	663,660,658,655,653,650,648,645,643,640,637,635,632,630,627,625,622,
	620,617,614,612,609,607,604,602,599,597,594,591,589,586,584,581,579,
	576,573,571,568,566,563,561,558,555,553,550,548,545,542,540,537,535,
	532,530,527,524,522,519,517,514,511,509,506,504,501,498,496,493,491,
	488,485,483,480,478,475,472,470,467,465,462,459,457,454,451,449,446,
	444,441,438,436,433,431,428,425,423,420,417,415,412,410,407,404,402,
	399,396,394,391,389,386,383,381,378,375,373,370,367,365,362,360,357,
	354,352,349,346,344,341,338,336,333,330,328,325,323,320,317,315,312,
	309,307,304,301,299,296,293,291,288,285,283,280,277,275,272,269,267,
	264,262,259,256,254,251,248,246,243,240,238,235,232,230,227,224,222,
	219,216,214,211,208,206,203,200,198,195,192,190,187,184,182,179,176,
	174,171,168,166,163,160,158,155,152,149,147,144,141,139,136,133,131,
	128,125,123,120,117,115,112,109,107,104,101,99,96,93,91,88,85,83,80,
	77,75,72,69,67,64,61,58,56,53,50,48,45,42,40,37,34,32,29,26,24,21,18,
	16,13,10,8,5,2,0,-3,-6,-9,-11,-14,-17,-19,-22,-25,-27,-30,-33,-35,
	-38,-41,-43,-46,-49,-51,-54,-57,-59,-62,-65,-68,-70,-73,-76,-78,-81,
	-84,-86,-89,-92,-94,-97,-100,-102,-105,-108,-110,-113,-116,-118,-121,
	-124,-126,-129,-132,-134,-137,-140,-142,-145,-148,-150,-153,-156,-159,
	-161,-164,-167,-169,-172,-175,-177,-180,-183,-185,-188,-191,-193,
	-196,-199,-201,-204,-207,-209,-212,-215,-217,-220,-223,-225,-228,-231,
	-233,-236,-239,-241,-244,-247,-249,-252,-255,-257,-260,-263,-265,-268,
	-270,-273,-276,-278,-281,-284,-286,-289,-292,-294,-297,-300,-302,
	-305,-308,-310,-313,-316,-318,-321,-324,-326,-329,-331,-334,-337,-339,
	-342,-345,-347,-350,-353,-355,-358,-361,-363,-366,-368,-371,-374,
	-376,-379,-382,-384,-387,-390,-392,-395,-397,-400,-403,-405,-408,-411,
	-413,-416,-418,-421,-424,-426,-429,-432,-434,-437,-439,-442,-445,-447,
	-450,-452,-455,-458,-460,-463,-466,-468,-471,-473,-476,-479,-481,
	-484,-486,-489,-492,-494,-497,-499,-502,-505,-507,-510,-512,-515,-518,
	-520,-523,-525,-528,-531,-533,-536,-538,-541,-543,-546,-549,-551,
	-554,-556,-559,-562,-564,-567,-569,-572,-574,-577,-580,-582,-585,-587,
	-590,-592,-595,-598,-600,-603,-605,-608,-610,-613,-615,-618,-621,-623,
	-626,-628,-631,-633,-636,-638,-641,-644,-646,-649,-651,-654,-656,
	-659,-661,-664,-666,-669,-671,-674,-677,-679,-682,-684,-687,-689,-692,
	-694,-697,-699,-702,-704,-707,-709,-712,-714,-717,-719,-722,-724,
	-727,-729,-732,-734,-737,-739,-742,-744,-747,-749,-752,-754,-757,-759,
	-762,-764,-767,-769,-772,-774,-777,-779,-782,-784,-787,-789,-792,-794,
	-797,-799,-802,-804,-806,-809,-811,-814,-816,-819,-821,-824,-826,
	-829,-831,-833,-836,-838,-841,-843,-846,-848,-851,-853,-855,-858,-860,
	-863,-865,-868,-870,-872,-875,-877,-880,-882,-885,-887,-889,-892,
	-894,-897,-899,-901,-904,-906,-909,-911,-914,-916,-918,-921,-923,-925,
	-928,-930,-933,-935,-937,-940,-942,-945,-947,-949,-952,-954,-956,-959,
	-961,-964,-966,-968,-971,-973,-975,-978,-980,-982,-985,-987,-989,
	-992,-994,-997,-999,-1001,-1004,-1006,-1008,-1011,-1013,-1015,-1018,
	-1020,-1022,-1025,-1027,-1029,-1031,-1034,-1036,-1038,-1041,-1043,-1045,
	-1048,-1050,-1052,-1055,-1057,-1059,-1061,-1064,-1066,-1068,-1071,
	-1073,-1075,-1077,-1080,-1082,-1084,-1087,-1089,-1091,-1093,-1096,
	-1098,-1100,-1102,-1105,-1107,-1109,-1111,-1114,-1116,-1118,-1120,-1123,
	-1125,-1127,-1129,-1132,-1134,-1136,-1138,-1141,-1143,-1145,-1147,
	-1149,-1152,-1154,-1156,-1158,-1160,-1163,-1165,-1167,-1169,-1172,
	-1174,-1176,-1178,-1180,-1182,-1185,-1187,-1189,-1191,-1193,-1196,-1198,
	-1200,-1202,-1204,-1206,-1209,-1211,-1213,-1215,-1217,-1219,-1222,
	-1224,-1226,-1228,-1230,-1232,-1234,-1237,-1239,-1241,-1243,-1245,
	-1247,-1249,-1251,-1254,-1256,-1258,-1260,-1262,-1264,-1266,-1268,-1271,
	-1273,-1275,-1277,-1279,-1281,-1283,-1285,-1287,-1289,-1291,-1294,
	-1296,-1298,-1300,-1302,-1304,-1306,-1308,-1310,-1312,-1314,-1316,
	-1318,-1320,-1322,-1324,-1326,-1329,-1331,-1333,-1335,-1337,-1339,-1341,
	-1343,-1345,-1347,-1349,-1351,-1353,-1355,-1357,-1359,-1361,-1363,
	-1365,-1367,-1369,-1371,-1373,-1375,-1377,-1379,-1381,-1383,-1385,
	-1387,-1389,-1391,-1393,-1395,-1397,-1399,-1400,-1402,-1404,-1406,-1408,
	-1410,-1412,-1414,-1416,-1418,-1420,-1422,-1424,-1426,-1428,-1430,
	-1431,-1433,-1435,-1437,-1439,-1441,-1443,-1445,-1447,-1449,-1451,
	-1452,-1454,-1456,-1458,-1460,-1462,-1464,-1466,-1467,-1469,-1471,-1473,
	-1475,-1477,-1479,-1481,-1482,-1484,-1486,-1488,-1490,-1492,-1493,
	-1495,-1497,-1499,-1501,-1503,-1504,-1506,-1508,-1510,-1512,-1513,
	-1515,-1517,-1519,-1521,-1522,-1524,-1526,-1528,-1530,-1531,-1533,-1535,
	-1537,-1538,-1540,-1542,-1544,-1546,-1547,-1549,-1551,-1553,-1554,
	-1556,-1558,-1560,-1561,-1563,-1565,-1566,-1568,-1570,-1572,-1573,
	-1575,-1577,-1579,-1580,-1582,-1584,-1585,-1587,-1589,-1590,-1592,-1594,
	-1595,-1597,-1599,-1600,-1602,-1604,-1606,-1607,-1609,-1610,-1612,
	-1614,-1615,-1617,-1619,-1620,-1622,-1624,-1625,-1627,-1629,-1630,
	-1632,-1633,-1635,-1637,-1638,-1640,-1641,-1643,-1645,-1646,-1648,-1649,
	-1651,-1653,-1654,-1656,-1657,-1659,-1661,-1662,-1664,-1665,-1667,
	-1668,-1670,-1671,-1673,-1675,-1676,-1678,-1679,-1681,-1682,-1684,
	-1685,-1687,-1688,-1690,-1691,-1693,-1694,-1696,-1697,-1699,-1700,-1702,
	-1703,-1705,-1706,-1708,-1709,-1711,-1712,-1714,-1715,-1717,-1718,
	-1720,-1721,-1722,-1724,-1725,-1727,-1728,-1730,-1731,-1733,-1734,
	-1735,-1737,-1738,-1740,-1741,-1742,-1744,-1745,-1747,-1748,-1750,-1751,
	-1752,-1754,-1755,-1756,-1758,-1759,-1761,-1762,-1763,-1765,-1766,
	-1767,-1769,-1770,-1771,-1773,-1774,-1775,-1777,-1778,-1779,-1781,
	-1782,-1783,-1785,-1786,-1787,-1789,-1790,-1791,-1793,-1794,-1795,-1796,
	-1798,-1799,-1800,-1802,-1803,-1804,-1805,-1807,-1808,-1809,-1810,
	-1812,-1813,-1814,-1815,-1817,-1818,-1819,-1820,-1822,-1823,-1824,
	-1825,-1826,-1828,-1829,-1830,-1831,-1833,-1834,-1835,-1836,-1837,-1838,
	-1840,-1841,-1842,-1843,-1844,-1846,-1847,-1848,-1849,-1850,-1851,
	-1852,-1854,-1855,-1856,-1857,-1858,-1859,-1860,-1861,-1863,-1864,
	-1865,-1866,-1867,-1868,-1869,-1870,-1871,-1873,-1874,-1875,-1876,-1877,
	-1878,-1879,-1880,-1881,-1882,-1883,-1884,-1885,-1886,-1887,-1888,
	-1890,-1891,-1892,-1893,-1894,-1895,-1896,-1897,-1898,-1899,-1900,
	-1901,-1902,-1903,-1904,-1905,-1906,-1907,-1908,-1909,-1910,-1911,-1912,
	-1912,-1913,-1914,-1915,-1916,-1917,-1918,-1919,-1920,-1921,-1922,
	-1923,-1924,-1925,-1926,-1927,-1927,-1928,-1929,-1930,-1931,-1932,
	-1933,-1934,-1935,-1935,-1936,-1937,-1938,-1939,-1940,-1941,-1942,-1942,
	-1943,-1944,-1945,-1946,-1947,-1947,-1948,-1949,-1950,-1951,-1952,
	-1952,-1953,-1954,-1955,-1956,-1956,-1957,-1958,-1959,-1960,-1960,
	-1961,-1962,-1963,-1963,-1964,-1965,-1966,-1966,-1967,-1968,-1969,-1969,
	-1970,-1971,-1972,-1972,-1973,-1974,-1974,-1975,-1976,-1977,-1977,
	-1978,-1979,-1979,-1980,-1981,-1981,-1982,-1983,-1983,-1984,-1985,
	-1985,-1986,-1987,-1987,-1988,-1989,-1989,-1990,-1991,-1991,-1992,-1993,
	-1993,-1994,-1994,-1995,-1996,-1996,-1997,-1997,-1998,-1999,-1999,
	-2000,-2000,-2001,-2001,-2002,-2003,-2003,-2004,-2004,-2005,-2005,
	-2006,-2006,-2007,-2008,-2008,-2009,-2009,-2010,-2010,-2011,-2011,-2012,
	-2012,-2013,-2013,-2014,-2014,-2015,-2015,-2016,-2016,-2017,-2017,
	-2018,-2018,-2018,-2019,-2019,-2020,-2020,-2021,-2021,-2022,-2022,
	-2022,-2023,-2023,-2024,-2024,-2025,-2025,-2025,-2026,-2026,-2027,-2027,
	-2027,-2028,-2028,-2028,-2029,-2029,-2030,-2030,-2030,-2031,-2031,
	-2031,-2032,-2032,-2032,-2033,-2033,-2033,-2034,-2034,-2034,-2035,
	-2035,-2035,-2036,-2036,-2036,-2036,-2037,-2037,-2037,-2038,-2038,-2038,
	-2038,-2039,-2039,-2039,-2039,-2040,-2040,-2040,-2040,-2041,-2041,
	-2041,-2041,-2042,-2042,-2042,-2042,-2042,-2043,-2043,-2043,-2043,
	-2043,-2044,-2044,-2044,-2044,-2044,-2044,-2045,-2045,-2045,-2045,-2045,
	-2045,-2046,-2046,-2046,-2046,-2046,-2046,-2046,-2046,-2047,-2047,
	-2047,-2047,-2047,-2047,-2047,-2047,-2047,-2047,-2047,-2047,-2047,
	-2047,-2047,-2047,-2047,-2047,-2047,-2047,-2047,-2047,-2047,-2047,-2047,
	-2047,-2047,-2047,-2047,-2047,-2047,-2047,-2047,-2047,-2047,-2047,
	-2047,-2047,-2047,-2047,-2047,-2047,-2047,-2047,-2047,-2047,-2047,
	-2047,-2047,-2047,-2047,-2047,-2047,-2047,-2047,-2047,-2047,-2047,-2047,
	-2047,-2047,-2047,-2047,-2047,-2047,-2047,-2047,-2046,-2046,-2046,
	-2046,-2046,-2046,-2046,-2046,-2045,-2045,-2045,-2045,-2045,-2045,
	-2044,-2044,-2044,-2044,-2044,-2044,-2043,-2043,-2043,-2043,-2043,-2042,
	-2042,-2042,-2042,-2042,-2041,-2041,-2041,-2041,-2040,-2040,-2040,
	-2040,-2039,-2039,-2039,-2039,-2038,-2038,-2038,-2038,-2037,-2037,
	-2037,-2036,-2036,-2036,-2036,-2035,-2035,-2035,-2034,-2034,-2034,-2033,
	-2033,-2033,-2032,-2032,-2032,-2031,-2031,-2031,-2030,-2030,-2030,
	-2029,-2029,-2028,-2028,-2028,-2027,-2027,-2027,-2026,-2026,-2025,
	-2025,-2025,-2024,-2024,-2023,-2023,-2022,-2022,-2022,-2021,-2021,-2020,
	-2020,-2019,-2019,-2018,-2018,-2018,-2017,-2017,-2016,-2016,-2015,
	-2015,-2014,-2014,-2013,-2013,-2012,-2012,-2011,-2011,-2010,-2010,
	-2009,-2009,-2008,-2008,-2007,-2006,-2006,-2005,-2005,-2004,-2004,-2003,
	-2003,-2002,-2001,-2001,-2000,-2000,-1999,-1999,-1998,-1997,-1997,
	-1996,-1996,-1995,-1994,-1994,-1993,-1993,-1992,-1991,-1991,-1990,
	-1989,-1989,-1988,-1987,-1987,-1986,-1985,-1985,-1984,-1983,-1983,-1982,
	-1981,-1981,-1980,-1979,-1979,-1978,-1977,-1977,-1976,-1975,-1974,
	-1974,-1973,-1972,-1972,-1971,-1970,-1969,-1969,-1968,-1967,-1966,
	-1966,-1965,-1964,-1963,-1963,-1962,-1961,-1960,-1960,-1959,-1958,-1957,
	-1956,-1956,-1955,-1954,-1953,-1952,-1952,-1951,-1950,-1949,-1948,
	-1947,-1947,-1946,-1945,-1944,-1943,-1942,-1942,-1941,-1940,-1939,
	-1938,-1937,-1936,-1935,-1935,-1934,-1933,-1932,-1931,-1930,-1929,-1928,
	-1927,-1927,-1926,-1925,-1924,-1923,-1922,-1921,-1920,-1919,-1918,
	-1917,-1916,-1915,-1914,-1913,-1912,-1912,-1911,-1910,-1909,-1908,
	-1907,-1906,-1905,-1904,-1903,-1902,-1901,-1900,-1899,-1898,-1897,-1896,
	-1895,-1894,-1893,-1892,-1891,-1890,-1888,-1887,-1886,-1885,-1884,
	-1883,-1882,-1881,-1880,-1879,-1878,-1877,-1876,-1875,-1874,-1873,
	-1871,-1870,-1869,-1868,-1867,-1866,-1865,-1864,-1863,-1861,-1860,-1859,
	-1858,-1857,-1856,-1855,-1854,-1852,-1851,-1850,-1849,-1848,-1847,
	-1846,-1844,-1843,-1842,-1841,-1840,-1838,-1837,-1836,-1835,-1834,
	-1833,-1831,-1830,-1829,-1828,-1826,-1825,-1824,-1823,-1822,-1820,-1819,
	-1818,-1817,-1815,-1814,-1813,-1812,-1810,-1809,-1808,-1807,-1805,
	-1804,-1803,-1802,-1800,-1799,-1798,-1796,-1795,-1794,-1793,-1791,
	-1790,-1789,-1787,-1786,-1785,-1783,-1782,-1781,-1779,-1778,-1777,-1775,
	-1774,-1773,-1771,-1770,-1769,-1767,-1766,-1765,-1763,-1762,-1761,
	-1759,-1758,-1756,-1755,-1754,-1752,-1751,-1750,-1748,-1747,-1745,
	-1744,-1742,-1741,-1740,-1738,-1737,-1735,-1734,-1733,-1731,-1730,-1728,
	-1727,-1725,-1724,-1722,-1721,-1720,-1718,-1717,-1715,-1714,-1712,
	-1711,-1709,-1708,-1706,-1705,-1703,-1702,-1700,-1699,-1697,-1696,
	-1694,-1693,-1691,-1690,-1688,-1687,-1685,-1684,-1682,-1681,-1679,-1678,
	-1676,-1675,-1673,-1671,-1670,-1668,-1667,-1665,-1664,-1662,-1661,
	-1659,-1657,-1656,-1654,-1653,-1651,-1649,-1648,-1646,-1645,-1643,
	-1641,-1640,-1638,-1637,-1635,-1633,-1632,-1630,-1629,-1627,-1625,-1624,
	-1622,-1620,-1619,-1617,-1615,-1614,-1612,-1610,-1609,-1607,-1606,
	-1604,-1602,-1600,-1599,-1597,-1595,-1594,-1592,-1590,-1589,-1587,
	-1585,-1584,-1582,-1580,-1579,-1577,-1575,-1573,-1572,-1570,-1568,-1566,
	-1565,-1563,-1561,-1560,-1558,-1556,-1554,-1553,-1551,-1549,-1547,
	-1546,-1544,-1542,-1540,-1538,-1537,-1535,-1533,-1531,-1530,-1528,
	-1526,-1524,-1522,-1521,-1519,-1517,-1515,-1513,-1512,-1510,-1508,-1506,
	-1504,-1503,-1501,-1499,-1497,-1495,-1493,-1492,-1490,-1488,-1486,
	-1484,-1482,-1481,-1479,-1477,-1475,-1473,-1471,-1469,-1467,-1466,
	-1464,-1462,-1460,-1458,-1456,-1454,-1452,-1451,-1449,-1447,-1445,-1443,
	-1441,-1439,-1437,-1435,-1433,-1431,-1430,-1428,-1426,-1424,-1422,
	-1420,-1418,-1416,-1414,-1412,-1410,-1408,-1406,-1404,-1402,-1400,
	-1399,-1397,-1395,-1393,-1391,-1389,-1387,-1385,-1383,-1381,-1379,-1377,
	-1375,-1373,-1371,-1369,-1367,-1365,-1363,-1361,-1359,-1357,-1355,
	-1353,-1351,-1349,-1347,-1345,-1343,-1341,-1339,-1337,-1335,-1333,
	-1331,-1329,-1326,-1324,-1322,-1320,-1318,-1316,-1314,-1312,-1310,-1308,
	-1306,-1304,-1302,-1300,-1298,-1296,-1294,-1291,-1289,-1287,-1285,
	-1283,-1281,-1279,-1277,-1275,-1273,-1271,-1268,-1266,-1264,-1262,
	-1260,-1258,-1256,-1254,-1251,-1249,-1247,-1245,-1243,-1241,-1239,-1237,
	-1234,-1232,-1230,-1228,-1226,-1224,-1222,-1219,-1217,-1215,-1213,
	-1211,-1209,-1206,-1204,-1202,-1200,-1198,-1196,-1193,-1191,-1189,
	-1187,-1185,-1182,-1180,-1178,-1176,-1174,-1172,-1169,-1167,-1165,-1163,
	-1160,-1158,-1156,-1154,-1152,-1149,-1147,-1145,-1143,-1141,-1138,
	-1136,-1134,-1132,-1129,-1127,-1125,-1123,-1120,-1118,-1116,-1114,
	-1111,-1109,-1107,-1105,-1102,-1100,-1098,-1096,-1093,-1091,-1089,-1087,
	-1084,-1082,-1080,-1077,-1075,-1073,-1071,-1068,-1066,-1064,-1061,
	-1059,-1057,-1055,-1052,-1050,-1048,-1045,-1043,-1041,-1038,-1036,
	-1034,-1031,-1029,-1027,-1024,-1022,-1020,-1018,-1015,-1013,-1011,-1008,
	-1006,-1004,-1001,-999,-997,-994,-992,-989,-987,-985,-982,-980,
	-978,-975,-973,-971,-968,-966,-964,-961,-959,-956,-954,-952,-949,-947,
	-945,-942,-940,-937,-935,-933,-930,-928,-925,-923,-921,-918,-916,-914,
	-911,-909,-906,-904,-901,-899,-897,-894,-892,-889,-887,-885,-882,
	-880,-877,-875,-872,-870,-868,-865,-863,-860,-858,-855,-853,-851,-848,
	-846,-843,-841,-838,-836,-833,-831,-829,-826,-824,-821,-819,-816,
	-814,-811,-809,-806,-804,-802,-799,-797,-794,-792,-789,-787,-784,-782,
	-779,-777,-774,-772,-769,-767,-764,-762,-759,-757,-754,-752,-749,-747,
	-744,-742,-739,-737,-734,-732,-729,-727,-724,-722,-719,-717,-714,
	-712,-709,-707,-704,-702,-699,-697,-694,-692,-689,-687,-684,-682,-679,
	-677,-674,-671,-669,-666,-664,-661,-659,-656,-654,-651,-649,-646,
	-644,-641,-638,-636,-633,-631,-628,-626,-623,-621,-618,-615,-613,-610,
	-608,-605,-603,-600,-598,-595,-592,-590,-587,-585,-582,-580,-577,-574,
	-572,-569,-567,-564,-562,-559,-556,-554,-551,-549,-546,-543,-541,
	-538,-536,-533,-531,-528,-525,-523,-520,-518,-515,-512,-510,-507,-505,
	-502,-499,-497,-494,-492,-489,-486,-484,-481,-479,-476,-473,-471,
	-468,-466,-463,-460,-458,-455,-452,-450,-447,-445,-442,-439,-437,-434,
	-432,-429,-426,-424,-421,-418,-416,-413,-411,-408,-405,-403,-400,-397,
	-395,-392,-390,-387,-384,-382,-379,-376,-374,-371,-368,-366,-363,
	-361,-358,-355,-353,-350,-347,-345,-342,-339,-337,-334,-331,-329,-326,
	-324,-321,-318,-316,-313,-310,-308,-305,-302,-300,-297,-294,-292,
	-289,-286,-284,-281,-278,-276,-273,-270,-268,-265,-263,-260,-257,-255,
	-252,-249,-247,-244,-241,-239,-236,-233,-231,-228,-225,-223,-220,-217,
	-215,-212,-209,-207,-204,-201,-199,-196,-193,-191,-188,-185,-183,
	-180,-177,-175,-172,-169,-167,-164,-161,-159,-156,-153,-150,-148,-145,
	-142,-140,-137,-134,-132,-129,-126,-124,-121,-118,-116,-113,-110,
	-108,-105,-102,-100,-97,-94,-92,-89,-86,-84,-81,-78,-76,-73,-70,-68,
	-65,-62,-59,-57,-54,-51,-49,-46,-43,-41,-38,-35,-33,-30,-27,-25,-22,
	-19,-17,-14,-11,-9,-6,-3,-1,2,5,8,10,13,16,18,21,24,26,29,32,34,37,40,
	42,45,48,50,53,56,58,61,64,67,69,72,75,77,80,83,85,88,91,93,96,99,
	101,104,107,109,112,115,117,120,123,125,128,131,133,136,139,141,144,
	147,149,152,155,158,160,163,166,168,171,174,176,179,182,184,187,190,
	192,195,198,200,203,206,208,211,214,216,219,222,224,227,230,232,235,
	238,240,243,246,248,251,254,256,259,262,264,267,269,272,275,277,280,
	283,285,288,291,293,296,299,301,304,307,309,312,315,317,320,323,325,
	328,330,333,336,338,341,344,346,349,352,354,357,360,362,365,367,370,
	373,375,378,381,383,386,389,391,394,396,399,402,404,407,410,412,415,
	417,420,423,425,428,431,433,436,438,441,444,446,449,451,454,457,459,
	462,465,467,470,472,475,478,480,483,485,488,491,493,496,498,501,504,
	506,509,511,514,517,519,522,524,527,530,532,535,537,540,542,545,548,
	550,553,555,558,561,563,566,568,571,573,576,579,581,584,586,589,591,
	594,597,599,602,604,607,609,612,614,617,620,622,625,627,630,632,635,
	637,640,643,645,648,650,653,655,658,660,663,665,668,670,673,676,678,
	681,683,686,688,691,693,696,698,701,703,706,708,711,713,716,718,721,
	723,726,728,731,733,736,738,741,743,746,748,751,753,756,758,761,763,
	766,768,771,773,776,778,781,783,786,788,791,793,796,798,801,803,805,
	808,810,813,815,818,820,823,825,828,830,832,835,837,840,842,845,847,
	850,852,854,857,859,862,864,867,869,871,874,876,879,881,884,886,888,
	891,893,896,898,900,903,905,908,910,913,915,917,920,922,924,927,929,
	932,934,936,939,941,944,946,948,951,953,955,958,960,963,965,967,970,
	972,974,977,979,981,984,986,988,991,993,996,998,1000,1003,1005,1007,
	1010,1012,1014,1017,1019,1021,1023,1026,1028,1030,1033,1035,1037,1040,
	1042,1044,1047,1049,1051,1054,1056,1058,1060,1063,1065,1067,1070,1072,
	1074,1076,1079,1081,1083,1086,1088,1090,1092,1095,1097,1099,1101,
	1104,1106,1108,1110,1113,1115,1117,1119,1122,1124,1126,1128,1131,1133,
	1135,1137,1140,1142,1144,1146,1148,1151,1153,1155,1157,1159,1162,
	1164,1166,1168,1171,1173,1175,1177,1179,1181,1184,1186,1188,1190,1192,
	1195,1197,1199,1201,1203,1205,1208,1210,1212,1214,1216,1218,1221,1223,
	1225,1227,1229,1231,1233,1236,1238,1240,1242,1244,1246,1248,1250,
	1253,1255,1257,1259,1261,1263,1265,1267,1270,1272,1274,1276,1278,1280,
	1282,1284,1286,1288,1290,1293,1295,1297,1299,1301,1303,1305,1307,
	1309,1311,1313,1315,1317,1319,1321,1323,1325,1328,1330,1332,1334,1336,
	1338,1340,1342,1344,1346,1348,1350,1352,1354,1356,1358,1360,1362,1364,
	1366,1368,1370,1372,1374,1376,1378,1380,1382,1384,1386,1388,1390,
	1392,1394,1396,1398,1399,1401,1403,1405,1407,1409,1411,1413,1415,1417,
	1419,1421,1423,1425,1427,1429,1430,1432,1434,1436,1438,1440,1442,
	1444,1446,1448,1450,1451,1453,1455,1457,1459,1461,1463,1465,1466,1468,
	1470,1472,1474,1476,1478,1480,1481,1483,1485,1487,1489,1491,1492,1494,
	1496,1498,1500,1502,1503,1505,1507,1509,1511,1512,1514,1516,1518,
	1520,1521,1523,1525,1527,1529,1530,1532,1534,1536,1537,1539,1541,1543,
	1545,1546,1548,1550,1552,1553,1555,1557,1559,1560,1562,1564,1565,
	1567,1569,1571,1572,1574,1576,1578,1579,1581,1583,1584,1586,1588,1589,
	1591,1593,1594,1596,1598,1599,1601,1603,1605,1606,1608,1609,1611,1613,
	1614,1616,1618,1619,1621,1623,1624,1626,1628,1629,1631,1632,1634,
	1636,1637,1639,1640,1642,1644,1645,1647,1648,1650,1652,1653,1655,1656,
	1658,1660,1661,1663,1664,1666,1667,1669,1670,1672,1674,1675,1677,
	1678,1680,1681,1683,1684,1686,1687,1689,1690,1692,1693,1695,1696,1698,
	1699,1701,1702,1704,1705,1707,1708,1710,1711,1713,1714,1716,1717,1719,
	1720,1721,1723,1724,1726,1727,1729,1730,1732,1733,1734,1736,1737,
	1739,1740,1741,1743,1744,1746,1747,1749,1750,1751,1753,1754,1755,1757,
	1758,1760,1761,1762,1764,1765,1766,1768,1769,1770,1772,1773,1774,
	1776,1777,1778,1780,1781,1782,1784,1785,1786,1788,1789,1790,1792,1793,
	1794,1795,1797,1798,1799,1801,1802,1803,1804,1806,1807,1808,1809,1811,
	1812,1813,1814,1816,1817,1818,1819,1821,1822,1823,1824,1825,1827,
	1828,1829,1830,1832,1833,1834,1835,1836,1837,1839,1840,1841,1842,1843,
	1845,1846,1847,1848,1849,1850,1851,1853,1854,1855,1856,1857,1858,
	1859,1860,1862,1863,1864,1865,1866,1867,1868,1869,1870,1872,1873,1874,
	1875,1876,1877,1878,1879,1880,1881,1882,1883,1884,1885,1886,1887,1889,
	1890,1891,1892,1893,1894,1895,1896,1897,1898,1899,1900,1901,1902,
	1903,1904,1905,1906,1907,1908,1909,1910,1911,1911,1912,1913,1914,1915,
	1916,1917,1918,1919,1920,1921,1922,1923,1924,1925,1926,1926,1927,
	1928,1929,1930,1931,1932,1933,1934,1934,1935,1936,1937,1938,1939,1940,
	1941,1941,1942,1943,1944,1945,1946,1946,1947,1948,1949,1950,1951,1951,
	1952,1953,1954,1955,1955,1956,1957,1958,1959,1959,1960,1961,1962,
	1962,1963,1964,1965,1965,1966,1967,1968,1968,1969,1970,1971,1971,1972,
	1973,1973,1974,1975,1976,1976,1977,1978,1978,1979,1980,1980,1981,
	1982,1982,1983,1984,1984,1985,1986,1986,1987,1988,1988,1989,1990,1990,
	1991,1992,1992,1993,1993,1994,1995,1995,1996,1996,1997,1998,1998,1999,
	1999,2000,2000,2001,2002,2002,2003,2003,2004,2004,2005,2005,2006,
	2007,2007,2008,2008,2009,2009,2010,2010,2011,2011,2012,2012,2013,2013,
	2014,2014,2015,2015,2016,2016,2017,2017,2017,2018,2018,2019,2019,
	2020,2020,2021,2021,2021,2022,2022,2023,2023,2024,2024,2024,2025,2025,
	2026,2026,2026,2027,2027,2027,2028,2028,2029,2029,2029,2030,2030,2030,
	2031,2031,2031,2032,2032,2032,2033,2033,2033,2034,2034,2034,2035,
	2035,2035,2035,2036,2036,2036,2037,2037,2037,2037,2038,2038,2038,2038,
	2039,2039,2039,2039,2040,2040,2040,2040,2041,2041,2041,2041,2041,
	2042,2042,2042,2042,2042,2043,2043,2043,2043,2043,2043,2044,2044,2044,
	2044,2044,2044,2045,2045,2045,2045,2045,2045,2045,2045,2046,2046,2046,
	2046,2046,2046,2046,2046,2046,2046,2047,2047,2047,2047,2047,2047,
	2047,2047,2047,2047,2047,2047,2047,2047,2047,2047,2047,2047,2047,2047,
	2047,2047,2047,
	};

int16_t const INV_TAN[4096]={
-600,-600,-600,-600,-600,-600,-599,-599,-599,-599,
	-599,-598,-598,-598,-598,-598,-598,-597,-597,-597,-597,-597,-596,-596,
	-596,-596,-596,-595,-595,-595,-595,-595,-594,-594,-594,-594,-594,
	-594,-593,-593,-593,-593,-593,-592,-592,-592,-592,-592,-591,-591,-591,
	-591,-591,-590,-590,-590,-590,-590,-590,-589,-589,-589,-589,-589,-588,
	-588,-588,-588,-588,-587,-587,-587,-587,-587,-586,-586,-586,-586,
	-586,-585,-585,-585,-585,-585,-585,-584,-584,-584,-584,-584,-583,-583,
	-583,-583,-583,-582,-582,-582,-582,-582,-581,-581,-581,-581,-581,
	-580,-580,-580,-580,-580,-579,-579,-579,-579,-579,-578,-578,-578,-578,
	-578,-577,-577,-577,-577,-577,-576,-576,-576,-576,-576,-575,-575,-575,
	-575,-575,-574,-574,-574,-574,-574,-573,-573,-573,-573,-573,-572,
	-572,-572,-572,-572,-571,-571,-571,-571,-571,-570,-570,-570,-570,-570,
	-569,-569,-569,-569,-569,-568,-568,-568,-568,-568,-567,-567,-567,
	-567,-567,-566,-566,-566,-566,-566,-565,-565,-565,-565,-565,-564,-564,
	-564,-564,-564,-563,-563,-563,-563,-563,-562,-562,-562,-562,-562,-561,
	-561,-561,-561,-560,-560,-560,-560,-560,-559,-559,-559,-559,-559,
	-558,-558,-558,-558,-558,-557,-557,-557,-557,-557,-556,-556,-556,-556,
	-556,-555,-555,-555,-555,-554,-554,-554,-554,-554,-553,-553,-553,
	-553,-553,-552,-552,-552,-552,-552,-551,-551,-551,-551,-550,-550,-550,
	-550,-550,-549,-549,-549,-549,-549,-548,-548,-548,-548,-548,-547,-547,
	-547,-547,-546,-546,-546,-546,-546,-545,-545,-545,-545,-545,-544,
	-544,-544,-544,-543,-543,-543,-543,-543,-542,-542,-542,-542,-542,-541,
	-541,-541,-541,-540,-540,-540,-540,-540,-539,-539,-539,-539,-539,
	-538,-538,-538,-538,-537,-537,-537,-537,-537,-536,-536,-536,-536,-535,
	-535,-535,-535,-535,-534,-534,-534,-534,-534,-533,-533,-533,-533,-532,
	-532,-532,-532,-532,-531,-531,-531,-531,-530,-530,-530,-530,-530,
	-529,-529,-529,-529,-528,-528,-528,-528,-528,-527,-527,-527,-527,-526,
	-526,-526,-526,-526,-525,-525,-525,-525,-524,-524,-524,-524,-524,
	-523,-523,-523,-523,-522,-522,-522,-522,-522,-521,-521,-521,-521,-520,
	-520,-520,-520,-519,-519,-519,-519,-519,-518,-518,-518,-518,-517,-517,
	-517,-517,-517,-516,-516,-516,-516,-515,-515,-515,-515,-515,-514,
	-514,-514,-514,-513,-513,-513,-513,-512,-512,-512,-512,-512,-511,-511,
	-511,-511,-510,-510,-510,-510,-509,-509,-509,-509,-509,-508,-508,
	-508,-508,-507,-507,-507,-507,-506,-506,-506,-506,-506,-505,-505,-505,
	-505,-504,-504,-504,-504,-503,-503,-503,-503,-502,-502,-502,-502,-502,
	-501,-501,-501,-501,-500,-500,-500,-500,-499,-499,-499,-499,-499,
	-498,-498,-498,-498,-497,-497,-497,-497,-496,-496,-496,-496,-495,-495,
	-495,-495,-494,-494,-494,-494,-494,-493,-493,-493,-493,-492,-492,
	-492,-492,-491,-491,-491,-491,-490,-490,-490,-490,-489,-489,-489,-489,
	-489,-488,-488,-488,-488,-487,-487,-487,-487,-486,-486,-486,-486,-485,
	-485,-485,-485,-484,-484,-484,-484,-483,-483,-483,-483,-482,-482,
	-482,-482,-481,-481,-481,-481,-481,-480,-480,-480,-480,-479,-479,-479,
	-479,-478,-478,-478,-478,-477,-477,-477,-477,-476,-476,-476,-476,
	-475,-475,-475,-475,-474,-474,-474,-474,-473,-473,-473,-473,-472,-472,
	-472,-472,-471,-471,-471,-471,-470,-470,-470,-470,-469,-469,-469,-469,
	-468,-468,-468,-468,-467,-467,-467,-467,-466,-466,-466,-466,-465,
	-465,-465,-465,-464,-464,-464,-464,-463,-463,-463,-463,-462,-462,-462,
	-462,-461,-461,-461,-461,-460,-460,-460,-460,-459,-459,-459,-459,
	-458,-458,-458,-458,-457,-457,-457,-457,-456,-456,-456,-456,-455,-455,
	-455,-455,-454,-454,-454,-453,-453,-453,-453,-452,-452,-452,-452,-451,
	-451,-451,-451,-450,-450,-450,-450,-449,-449,-449,-449,-448,-448,
	-448,-448,-447,-447,-447,-447,-446,-446,-446,-445,-445,-445,-445,-444,
	-444,-444,-444,-443,-443,-443,-443,-442,-442,-442,-442,-441,-441,
	-441,-441,-440,-440,-440,-439,-439,-439,-439,-438,-438,-438,-438,-437,
	-437,-437,-437,-436,-436,-436,-435,-435,-435,-435,-434,-434,-434,-434,
	-433,-433,-433,-433,-432,-432,-432,-432,-431,-431,-431,-430,-430,
	-430,-430,-429,-429,-429,-429,-428,-428,-428,-428,-427,-427,-427,-426,
	-426,-426,-426,-425,-425,-425,-425,-424,-424,-424,-423,-423,-423,
	-423,-422,-422,-422,-422,-421,-421,-421,-420,-420,-420,-420,-419,-419,
	-419,-419,-418,-418,-418,-418,-417,-417,-417,-416,-416,-416,-416,-415,
	-415,-415,-415,-414,-414,-414,-413,-413,-413,-413,-412,-412,-412,
	-411,-411,-411,-411,-410,-410,-410,-410,-409,-409,-409,-408,-408,-408,
	-408,-407,-407,-407,-407,-406,-406,-406,-405,-405,-405,-405,-404,
	-404,-404,-403,-403,-403,-403,-402,-402,-402,-402,-401,-401,-401,-400,
	-400,-400,-400,-399,-399,-399,-398,-398,-398,-398,-397,-397,-397,-396,
	-396,-396,-396,-395,-395,-395,-394,-394,-394,-394,-393,-393,-393,
	-393,-392,-392,-392,-391,-391,-391,-391,-390,-390,-390,-389,-389,-389,
	-389,-388,-388,-388,-387,-387,-387,-387,-386,-386,-386,-385,-385,
	-385,-385,-384,-384,-384,-383,-383,-383,-383,-382,-382,-382,-381,-381,
	-381,-381,-380,-380,-380,-379,-379,-379,-378,-378,-378,-378,-377,-377,
	-377,-376,-376,-376,-376,-375,-375,-375,-374,-374,-374,-374,-373,
	-373,-373,-372,-372,-372,-372,-371,-371,-371,-370,-370,-370,-369,-369,
	-369,-369,-368,-368,-368,-367,-367,-367,-367,-366,-366,-366,-365,
	-365,-365,-364,-364,-364,-364,-363,-363,-363,-362,-362,-362,-362,-361,
	-361,-361,-360,-360,-360,-359,-359,-359,-359,-358,-358,-358,-357,-357,
	-357,-356,-356,-356,-356,-355,-355,-355,-354,-354,-354,-354,-353,
	-353,-353,-352,-352,-352,-351,-351,-351,-351,-350,-350,-350,-349,-349,
	-349,-348,-348,-348,-348,-347,-347,-347,-346,-346,-346,-345,-345,
	-345,-344,-344,-344,-344,-343,-343,-343,-342,-342,-342,-341,-341,-341,
	-341,-340,-340,-340,-339,-339,-339,-338,-338,-338,-338,-337,-337,-337,
	-336,-336,-336,-335,-335,-335,-334,-334,-334,-334,-333,-333,-333,
	-332,-332,-332,-331,-331,-331,-330,-330,-330,-330,-329,-329,-329,-328,
	-328,-328,-327,-327,-327,-326,-326,-326,-326,-325,-325,-325,-324,
	-324,-324,-323,-323,-323,-322,-322,-322,-321,-321,-321,-321,-320,-320,
	-320,-319,-319,-319,-318,-318,-318,-317,-317,-317,-316,-316,-316,-316,
	-315,-315,-315,-314,-314,-314,-313,-313,-313,-312,-312,-312,-311,
	-311,-311,-311,-310,-310,-310,-309,-309,-309,-308,-308,-308,-307,-307,
	-307,-306,-306,-306,-305,-305,-305,-305,-304,-304,-304,-303,-303,
	-303,-302,-302,-302,-301,-301,-301,-300,-300,-300,-299,-299,-299,-298,
	-298,-298,-298,-297,-297,-297,-296,-296,-296,-295,-295,-295,-294,-294,
	-294,-293,-293,-293,-292,-292,-292,-291,-291,-291,-290,-290,-290,
	-290,-289,-289,-289,-288,-288,-288,-287,-287,-287,-286,-286,-286,-285,
	-285,-285,-284,-284,-284,-283,-283,-283,-282,-282,-282,-281,-281,
	-281,-280,-280,-280,-279,-279,-279,-278,-278,-278,-278,-277,-277,-277,
	-276,-276,-276,-275,-275,-275,-274,-274,-274,-273,-273,-273,-272,-272,
	-272,-271,-271,-271,-270,-270,-270,-269,-269,-269,-268,-268,-268,
	-267,-267,-267,-266,-266,-266,-265,-265,-265,-264,-264,-264,-263,-263,
	-263,-262,-262,-262,-261,-261,-261,-260,-260,-260,-259,-259,-259,
	-258,-258,-258,-257,-257,-257,-256,-256,-256,-255,-255,-255,-254,-254,
	-254,-253,-253,-253,-252,-252,-252,-251,-251,-251,-250,-250,-250,-249,
	-249,-249,-248,-248,-248,-247,-247,-247,-246,-246,-246,-245,-245,
	-245,-244,-244,-244,-243,-243,-243,-242,-242,-242,-241,-241,-241,-240,
	-240,-240,-239,-239,-239,-238,-238,-238,-237,-237,-237,-236,-236,
	-236,-235,-235,-235,-234,-234,-234,-233,-233,-233,-232,-232,-232,-231,
	-231,-231,-230,-230,-230,-229,-229,-228,-228,-228,-227,-227,-227,-226,
	-226,-226,-225,-225,-225,-224,-224,-224,-223,-223,-223,-222,-222,
	-222,-221,-221,-221,-220,-220,-220,-219,-219,-219,-218,-218,-218,-217,
	-217,-217,-216,-216,-215,-215,-215,-214,-214,-214,-213,-213,-213,
	-212,-212,-212,-211,-211,-211,-210,-210,-210,-209,-209,-209,-208,-208,
	-208,-207,-207,-206,-206,-206,-205,-205,-205,-204,-204,-204,-203,-203,
	-203,-202,-202,-202,-201,-201,-201,-200,-200,-200,-199,-199,-198,
	-198,-198,-197,-197,-197,-196,-196,-196,-195,-195,-195,-194,-194,-194,
	-193,-193,-193,-192,-192,-192,-191,-191,-190,-190,-190,-189,-189,
	-189,-188,-188,-188,-187,-187,-187,-186,-186,-186,-185,-185,-184,-184,
	-184,-183,-183,-183,-182,-182,-182,-181,-181,-181,-180,-180,-180,-179,
	-179,-178,-178,-178,-177,-177,-177,-176,-176,-176,-175,-175,-175,
	-174,-174,-174,-173,-173,-172,-172,-172,-171,-171,-171,-170,-170,-170,
	-169,-169,-169,-168,-168,-168,-167,-167,-166,-166,-166,-165,-165,
	-165,-164,-164,-164,-163,-163,-163,-162,-162,-161,-161,-161,-160,-160,
	-160,-159,-159,-159,-158,-158,-158,-157,-157,-156,-156,-156,-155,-155,
	-155,-154,-154,-154,-153,-153,-153,-152,-152,-151,-151,-151,-150,
	-150,-150,-149,-149,-149,-148,-148,-147,-147,-147,-146,-146,-146,-145,
	-145,-145,-144,-144,-144,-143,-143,-142,-142,-142,-141,-141,-141,
	-140,-140,-140,-139,-139,-138,-138,-138,-137,-137,-137,-136,-136,-136,
	-135,-135,-135,-134,-134,-133,-133,-133,-132,-132,-132,-131,-131,-131,
	-130,-130,-129,-129,-129,-128,-128,-128,-127,-127,-127,-126,-126,
	-125,-125,-125,-124,-124,-124,-123,-123,-123,-122,-122,-121,-121,-121,
	-120,-120,-120,-119,-119,-119,-118,-118,-117,-117,-117,-116,-116,
	-116,-115,-115,-115,-114,-114,-113,-113,-113,-112,-112,-112,-111,-111,
	-111,-110,-110,-109,-109,-109,-108,-108,-108,-107,-107,-106,-106,-106,
	-105,-105,-105,-104,-104,-104,-103,-103,-102,-102,-102,-101,-101,
	-101,-100,-100,-100,-99,-99,-98,-98,-98,-97,-97,-97,-96,-96,-96,-95,
	-95,-94,-94,-94,-93,-93,-93,-92,-92,-91,-91,-91,-90,-90,-90,-89,-89,
	-89,-88,-88,-87,-87,-87,-86,-86,-86,-85,-85,-84,-84,-84,-83,-83,-83,
	-82,-82,-82,-81,-81,-80,-80,-80,-79,-79,-79,-78,-78,-77,-77,-77,-76,
	-76,-76,-75,-75,-74,-74,-74,-73,-73,-73,-72,-72,-72,-71,-71,-70,-70,
	-70,-69,-69,-69,-68,-68,-67,-67,-67,-66,-66,-66,-65,-65,-65,-64,-64,
	-63,-63,-63,-62,-62,-62,-61,-61,-60,-60,-60,-59,-59,-59,-58,-58,-57,
	-57,-57,-56,-56,-56,-55,-55,-54,-54,-54,-53,-53,-53,-52,-52,-52,-51,
	-51,-50,-50,-50,-49,-49,-49,-48,-48,-47,-47,-47,-46,-46,-46,-45,-45,
	-44,-44,-44,-43,-43,-43,-42,-42,-41,-41,-41,-40,-40,-40,-39,-39,-39,
	-38,-38,-37,-37,-37,-36,-36,-36,-35,-35,-34,-34,-34,-33,-33,-33,-32,
	-32,-31,-31,-31,-30,-30,-30,-29,-29,-28,-28,-28,-27,-27,-27,-26,-26,
	-25,-25,-25,-24,-24,-24,-23,-23,-23,-22,-22,-21,-21,-21,-20,-20,-20,
	-19,-19,-18,-18,-18,-17,-17,-17,-16,-16,-15,-15,-15,-14,-14,-14,-13,
	-13,-12,-12,-12,-11,-11,-11,-10,-10,-9,-9,-9,-8,-8,-8,-7,-7,-6,-6,-6,
	-5,-5,-5,-4,-4,-3,-3,-3,-2,-2,-2,-1,-1,0,0,0,1,1,1,2,2,2,3,3,4,4,4,
	5,5,5,6,6,7,7,7,8,8,8,9,9,10,10,10,11,11,11,12,12,13,13,13,14,14,14,
	15,15,16,16,16,17,17,17,18,18,19,19,19,20,20,20,21,21,22,22,22,23,23,
	23,24,24,24,25,25,26,26,26,27,27,27,28,28,29,29,29,30,30,30,31,31,
	32,32,32,33,33,33,34,34,35,35,35,36,36,36,37,37,38,38,38,39,39,39,40,
	40,40,41,41,42,42,42,43,43,43,44,44,45,45,45,46,46,46,47,47,48,48,48,
	49,49,49,50,50,51,51,51,52,52,52,53,53,53,54,54,55,55,55,56,56,56,
	57,57,58,58,58,59,59,59,60,60,61,61,61,62,62,62,63,63,64,64,64,65,65,
	65,66,66,66,67,67,68,68,68,69,69,69,70,70,71,71,71,72,72,72,73,73,73,
	74,74,75,75,75,76,76,76,77,77,78,78,78,79,79,79,80,80,81,81,81,82,
	82,82,83,83,83,84,84,85,85,85,86,86,86,87,87,88,88,88,89,89,89,90,90,
	90,91,91,92,92,92,93,93,93,94,94,95,95,95,96,96,96,97,97,97,98,98,99,
	99,99,100,100,100,101,101,101,102,102,103,103,103,104,104,104,105,
	105,105,106,106,107,107,107,108,108,108,109,109,110,110,110,111,111,
	111,112,112,112,113,113,114,114,114,115,115,115,116,116,116,117,117,
	118,118,118,119,119,119,120,120,120,121,121,122,122,122,123,123,123,
	124,124,124,125,125,126,126,126,127,127,127,128,128,128,129,129,130,
	130,130,131,131,131,132,132,132,133,133,134,134,134,135,135,135,136,
	136,136,137,137,137,138,138,139,139,139,140,140,140,141,141,141,142,
	142,143,143,143,144,144,144,145,145,145,146,146,146,147,147,148,148,
	148,149,149,149,150,150,150,151,151,152,152,152,153,153,153,154,154,
	154,155,155,155,156,156,157,157,157,158,158,158,159,159,159,160,160,
	160,161,161,162,162,162,163,163,163,164,164,164,165,165,165,166,166,
	167,167,167,168,168,168,169,169,169,170,170,170,171,171,171,172,172,
	173,173,173,174,174,174,175,175,175,176,176,176,177,177,177,178,178,
	179,179,179,180,180,180,181,181,181,182,182,182,183,183,183,184,184,
	185,185,185,186,186,186,187,187,187,188,188,188,189,189,189,190,190,
	191,191,191,192,192,192,193,193,193,194,194,194,195,195,195,196,196,
	196,197,197,197,198,198,199,199,199,200,200,200,201,201,201,202,202,
	202,203,203,203,204,204,204,205,205,205,206,206,207,207,207,208,208,
	208,209,209,209,210,210,210,211,211,211,212,212,212,213,213,213,214,
	214,214,215,215,216,216,216,217,217,217,218,218,218,219,219,219,220,
	220,220,221,221,221,222,222,222,223,223,223,224,224,224,225,225,225,
	226,226,226,227,227,227,228,228,229,229,229,230,230,230,231,231,231,
	232,232,232,233,233,233,234,234,234,235,235,235,236,236,236,237,237,
	237,238,238,238,239,239,239,240,240,240,241,241,241,242,242,242,243,
	243,243,244,244,244,245,245,245,246,246,246,247,247,247,248,248,248,
	249,249,249,250,250,250,251,251,251,252,252,252,253,253,253,254,254,
	254,255,255,255,256,256,256,257,257,257,258,258,258,259,259,259,260,
	260,260,261,261,261,262,262,262,263,263,263,264,264,264,265,265,265,
	266,266,266,267,267,267,268,268,268,269,269,269,270,270,270,271,271,
	271,272,272,272,273,273,273,274,274,274,275,275,275,276,276,276,277,
	277,277,277,278,278,278,279,279,279,280,280,280,281,281,281,282,282,
	282,283,283,283,284,284,284,285,285,285,286,286,286,287,287,287,288,
	288,288,289,289,289,289,290,290,290,291,291,291,292,292,292,293,293,
	293,294,294,294,295,295,295,296,296,296,297,297,297,297,298,298,298,
	299,299,299,300,300,300,301,301,301,302,302,302,303,303,303,304,304,
	304,304,305,305,305,306,306,306,307,307,307,308,308,308,309,309,309,
	310,310,310,310,311,311,311,312,312,312,313,313,313,314,314,314,315,
	315,315,315,316,316,316,317,317,317,318,318,318,319,319,319,320,320,
	320,320,321,321,321,322,322,322,323,323,323,324,324,324,325,325,325,
	325,326,326,326,327,327,327,328,328,328,329,329,329,329,330,330,330,
	331,331,331,332,332,332,333,333,333,333,334,334,334,335,335,335,336,
	336,336,337,337,337,337,338,338,338,339,339,339,340,340,340,340,341,
	341,341,342,342,342,343,343,343,343,344,344,344,345,345,345,346,346,
	346,347,347,347,347,348,348,348,349,349,349,350,350,350,350,351,351,
	351,352,352,352,353,353,353,353,354,354,354,355,355,355,355,356,356,
	356,357,357,357,358,358,358,358,359,359,359,360,360,360,361,361,361,
	361,362,362,362,363,363,363,363,364,364,364,365,365,365,366,366,366,
	366,367,367,367,368,368,368,368,369,369,369,370,370,370,371,371,371,
	371,372,372,372,373,373,373,373,374,374,374,375,375,375,375,376,376,
	376,377,377,377,377,378,378,378,379,379,379,380,380,380,380,381,381,
	381,382,382,382,382,383,383,383,384,384,384,384,385,385,385,386,386,
	386,386,387,387,387,388,388,388,388,389,389,389,390,390,390,390,391,
	391,391,392,392,392,392,393,393,393,393,394,394,394,395,395,395,395,
	396,396,396,397,397,397,397,398,398,398,399,399,399,399,400,400,400,
	401,401,401,401,402,402,402,402,403,403,403,404,404,404,404,405,405,
	405,406,406,406,406,407,407,407,407,408,408,408,409,409,409,409,410,
	410,410,410,411,411,411,412,412,412,412,413,413,413,414,414,414,414,
	415,415,415,415,416,416,416,417,417,417,417,418,418,418,418,419,419,
	419,419,420,420,420,421,421,421,421,422,422,422,422,423,423,423,424,
	424,424,424,425,425,425,425,426,426,426,427,427,427,427,428,428,428,
	428,429,429,429,429,430,430,430,431,431,431,431,432,432,432,432,433,
	433,433,433,434,434,434,434,435,435,435,436,436,436,436,437,437,437,
	437,438,438,438,438,439,439,439,440,440,440,440,441,441,441,441,442,
	442,442,442,443,443,443,443,444,444,444,444,445,445,445,446,446,446,
	446,447,447,447,447,448,448,448,448,449,449,449,449,450,450,450,450,
	451,451,451,451,452,452,452,452,453,453,453,454,454,454,454,455,455,
	455,455,456,456,456,456,457,457,457,457,458,458,458,458,459,459,459,
	459,460,460,460,460,461,461,461,461,462,462,462,462,463,463,463,463,
	464,464,464,464,465,465,465,465,466,466,466,466,467,467,467,467,468,
	468,468,468,469,469,469,469,470,470,470,470,471,471,471,471,472,472,
	472,472,473,473,473,473,474,474,474,474,475,475,475,475,476,476,476,
	476,477,477,477,477,478,478,478,478,479,479,479,479,480,480,480,480,
	480,481,481,481,481,482,482,482,482,483,483,483,483,484,484,484,484,
	485,485,485,485,486,486,486,486,487,487,487,487,488,488,488,488,488,
	489,489,489,489,490,490,490,490,491,491,491,491,492,492,492,492,493,
	493,493,493,493,494,494,494,494,495,495,495,495,496,496,496,496,497,
	497,497,497,498,498,498,498,498,499,499,499,499,500,500,500,500,501,
	501,501,501,501,502,502,502,502,503,503,503,503,504,504,504,504,505,
	505,505,505,505,506,506,506,506,507,507,507,507,508,508,508,508,508,
	509,509,509,509,510,510,510,510,511,511,511,511,511,512,512,512,512,
	513,513,513,513,514,514,514,514,514,515,515,515,515,516,516,516,516,
	516,517,517,517,517,518,518,518,518,518,519,519,519,519,520,520,520,
	520,521,521,521,521,521,522,522,522,522,523,523,523,523,523,524,524,
	524,524,525,525,525,525,525,526,526,526,526,527,527,527,527,527,528,
	528,528,528,529,529,529,529,529,530,530,530,530,531,531,531,531,531,
	532,532,532,532,533,533,533,533,533,534,534,534,534,534,535,535,535,
	535,536,536,536,536,536,537,537,537,537,538,538,538,538,538,539,539,
	539,539,539,540,540,540,540,541,541,541,541,541,542,542,542,542,542,
	543,543,543,543,544,544,544,544,544,545,545,545,545,545,546,546,546,
	546,547,547,547,547,547,548,548,548,548,548,549,549,549,549,549,550,
	550,550,550,551,551,551,551,551,552,552,552,552,552,553,553,553,553,
	553,554,554,554,554,555,555,555,555,555,556,556,556,556,556,557,557,
	557,557,557,558,558,558,558,558,559,559,559,559,559,560,560,560,560,
	561,561,561,561,561,562,562,562,562,562,563,563,563,563,563,564,564,
	564,564,564,565,565,565,565,565,566,566,566,566,566,567,567,567,567,
	567,568,568,568,568,568,569,569,569,569,569,570,570,570,570,570,571,
	571,571,571,571,572,572,572,572,572,573,573,573,573,573,574,574,574,
	574,574,575,575,575,575,575,576,576,576,576,576,577,577,577,577,577,
	578,578,578,578,578,579,579,579,579,579,580,580,580,580,580,581,581,
	581,581,581,582,582,582,582,582,583,583,583,583,583,584,584,584,584,
	584,584,585,585,585,585,585,586,586,586,586,586,587,587,587,587,587,
	588,588,588,588,588,589,589,589,589,589,589,590,590,590,590,590,591,
	591,591,591,591,592,592,592,592,592,593,593,593,593,593,593,594,594,
	594,594,594,595,595,595,595,595,596,596,596,596,596,597,597,597,597,
	597,597,598,598,598,598,598,599,599,599,599,599,
	};

int16_t const RADICAL[4096]={
0,64,90,110,128,143,156,169,181,192,202,212,
	221,230,239,247,256,263,271,278,286,293,300,306,313,320,326,332,338,
	344,350,356,362,367,373,378,384,389,394,399,404,409,414,419,424,429,
	434,438,443,448,452,457,461,465,470,474,478,483,487,491,495,499,503,
	507,512,515,519,523,527,531,535,539,543,546,550,554,557,561,565,568,
	572,576,579,583,586,590,593,596,600,603,607,610,613,617,620,623,627,
	630,633,636,640,643,646,649,652,655,658,662,665,668,671,674,677,680,
	683,686,689,692,695,698,701,704,706,709,712,715,718,721,724,726,729,
	732,735,738,740,743,746,749,751,754,757,759,762,765,768,770,773,775,
	778,781,783,786,789,791,794,796,799,801,804,807,809,812,814,817,819,
	822,824,827,829,832,834,836,839,841,844,846,849,851,853,856,858,861,
	863,865,868,870,872,875,877,879,882,884,886,889,891,893,896,898,900,
	902,905,907,909,911,914,916,918,920,923,925,927,929,931,934,936,938,
	940,942,944,947,949,951,953,955,957,960,962,964,966,968,970,972,974,
	976,979,981,983,985,987,989,991,993,995,997,999,1001,1003,1005,1007,
	1009,1011,1013,1015,1017,1019,1021,1024,1025,1027,1029,1031,1033,1035,
	1037,1039,1041,1043,1045,1047,1049,1051,1053,1055,1057,1059,1061,1063,
	1065,1067,1069,1070,1072,1074,1076,1078,1080,1082,1084,1086,1088,
	1089,1091,1093,1095,1097,1099,1101,1102,1104,1106,1108,1110,1112,1114,
	1115,1117,1119,1121,1123,1125,1126,1128,1130,1132,1134,1135,1137,
	1139,1141,1143,1144,1146,1148,1150,1152,1153,1155,1157,1159,1160,1162,
	1164,1166,1167,1169,1171,1173,1174,1176,1178,1180,1181,1183,1185,1187,
	1188,1190,1192,1193,1195,1197,1199,1200,1202,1204,1205,1207,1209,
	1210,1212,1214,1216,1217,1219,1221,1222,1224,1226,1227,1229,1231,1232,
	1234,1236,1237,1239,1241,1242,1244,1245,1247,1249,1250,1252,1254,
	1255,1257,1259,1260,1262,1263,1265,1267,1268,1270,1271,1273,1275,1276,
	1278,1280,1281,1283,1284,1286,1287,1289,1291,1292,1294,1295,1297,1299,
	1300,1302,1303,1305,1306,1308,1310,1311,1313,1314,1316,1317,1319,
	1320,1322,1324,1325,1327,1328,1330,1331,1333,1334,1336,1337,1339,1340,
	1342,1344,1345,1347,1348,1350,1351,1353,1354,1356,1357,1359,1360,
	1362,1363,1365,1366,1368,1369,1371,1372,1374,1375,1377,1378,1380,1381,
	1383,1384,1386,1387,1388,1390,1391,1393,1394,1396,1397,1399,1400,1402,
	1403,1405,1406,1408,1409,1410,1412,1413,1415,1416,1418,1419,1421,
	1422,1423,1425,1426,1428,1429,1431,1432,1433,1435,1436,1438,1439,1441,
	1442,1443,1445,1446,1448,1449,1450,1452,1453,1455,1456,1458,1459,
	1460,1462,1463,1465,1466,1467,1469,1470,1472,1473,1474,1476,1477,1478,
	1480,1481,1483,1484,1485,1487,1488,1489,1491,1492,1494,1495,1496,1498,
	1499,1500,1502,1503,1505,1506,1507,1509,1510,1511,1513,1514,1515,
	1517,1518,1519,1521,1522,1523,1525,1526,1527,1529,1530,1531,1533,1534,
	1536,1537,1538,1539,1541,1542,1543,1545,1546,1547,1549,1550,1551,
	1553,1554,1555,1557,1558,1559,1561,1562,1563,1565,1566,1567,1568,1570,
	1571,1572,1574,1575,1576,1578,1579,1580,1581,1583,1584,1585,1587,1588,
	1589,1591,1592,1593,1594,1596,1597,1598,1600,1601,1602,1603,1605,
	1606,1607,1608,1610,1611,1612,1614,1615,1616,1617,1619,1620,1621,1622,
	1624,1625,1626,1627,1629,1630,1631,1632,1634,1635,1636,1637,1639,
	1640,1641,1642,1644,1645,1646,1647,1649,1650,1651,1652,1654,1655,1656,
	1657,1659,1660,1661,1662,1664,1665,1666,1667,1668,1670,1671,1672,1673,
	1675,1676,1677,1678,1679,1681,1682,1683,1684,1686,1687,1688,1689,
	1690,1692,1693,1694,1695,1696,1698,1699,1700,1701,1702,1704,1705,1706,
	1707,1708,1710,1711,1712,1713,1714,1716,1717,1718,1719,1720,1722,
	1723,1724,1725,1726,1728,1729,1730,1731,1732,1733,1735,1736,1737,1738,
	1739,1740,1742,1743,1744,1745,1746,1748,1749,1750,1751,1752,1753,1755,
	1756,1757,1758,1759,1760,1762,1763,1764,1765,1766,1767,1768,1770,
	1771,1772,1773,1774,1775,1777,1778,1779,1780,1781,1782,1783,1785,1786,
	1787,1788,1789,1790,1792,1793,1794,1795,1796,1797,1798,1799,1801,
	1802,1803,1804,1805,1806,1807,1809,1810,1811,1812,1813,1814,1815,1816,
	1818,1819,1820,1821,1822,1823,1824,1825,1827,1828,1829,1830,1831,1832,
	1833,1834,1836,1837,1838,1839,1840,1841,1842,1843,1844,1846,1847,
	1848,1849,1850,1851,1852,1853,1854,1856,1857,1858,1859,1860,1861,1862,
	1863,1864,1865,1867,1868,1869,1870,1871,1872,1873,1874,1875,1876,
	1877,1879,1880,1881,1882,1883,1884,1885,1886,1887,1888,1889,1890,1892,
	1893,1894,1895,1896,1897,1898,1899,1900,1901,1902,1903,1905,1906,1907,
	1908,1909,1910,1911,1912,1913,1914,1915,1916,1917,1918,1920,1921,
	1922,1923,1924,1925,1926,1927,1928,1929,1930,1931,1932,1933,1934,1935,
	1936,1938,1939,1940,1941,1942,1943,1944,1945,1946,1947,1948,1949,
	1950,1951,1952,1953,1954,1955,1956,1958,1959,1960,1961,1962,1963,1964,
	1965,1966,1967,1968,1969,1970,1971,1972,1973,1974,1975,1976,1977,1978,
	1979,1980,1981,1982,1984,1985,1986,1987,1988,1989,1990,1991,1992,
	1993,1994,1995,1996,1997,1998,1999,2000,2001,2002,2003,2004,2005,2006,
	2007,2008,2009,2010,2011,2012,2013,2014,2015,2016,2017,2018,2019,
	2020,2021,2022,2023,2024,2025,2026,2027,2028,2029,2030,2031,2032,2033,
	2034,2035,2036,2037,2038,2039,2040,2041,2042,2043,2044,2045,2046,2048,
	2048,2049,2050,2051,2052,2053,2054,2055,2056,2057,2058,2059,2060,
	2061,2062,2063,2064,2065,2066,2067,2068,2069,2070,2071,2072,2073,2074,
	2075,2076,2077,2078,2079,2080,2081,2082,2083,2084,2085,2086,2087,
	2088,2089,2090,2091,2092,2093,2094,2095,2096,2097,2098,2099,2100,2101,
	2102,2103,2104,2105,2106,2107,2108,2109,2110,2111,2112,2112,2113,2114,
	2115,2116,2117,2118,2119,2120,2121,2122,2123,2124,2125,2126,2127,
	2128,2129,2130,2131,2132,2133,2134,2135,2136,2137,2138,2138,2139,2140,
	2141,2142,2143,2144,2145,2146,2147,2148,2149,2150,2151,2152,2153,
	2154,2155,2156,2157,2158,2158,2159,2160,2161,2162,2163,2164,2165,2166,
	2167,2168,2169,2170,2171,2172,2173,2174,2175,2176,2176,2177,2178,2179,
	2180,2181,2182,2183,2184,2185,2186,2187,2188,2189,2190,2191,2191,
	2192,2193,2194,2195,2196,2197,2198,2199,2200,2201,2202,2203,2204,2204,
	2205,2206,2207,2208,2209,2210,2211,2212,2213,2214,2215,2216,2217,
	2217,2218,2219,2220,2221,2222,2223,2224,2225,2226,2227,2228,2229,2229,
	2230,2231,2232,2233,2234,2235,2236,2237,2238,2239,2240,2240,2241,2242,
	2243,2244,2245,2246,2247,2248,2249,2250,2250,2251,2252,2253,2254,
	2255,2256,2257,2258,2259,2260,2260,2261,2262,2263,2264,2265,2266,2267,
	2268,2269,2269,2270,2271,2272,2273,2274,2275,2276,2277,2278,2278,
	2279,2280,2281,2282,2283,2284,2285,2286,2287,2287,2288,2289,2290,2291,
	2292,2293,2294,2295,2295,2296,2297,2298,2299,2300,2301,2302,2303,2304,
	2304,2305,2306,2307,2308,2309,2310,2311,2311,2312,2313,2314,2315,
	2316,2317,2318,2319,2319,2320,2321,2322,2323,2324,2325,2326,2326,2327,
	2328,2329,2330,2331,2332,2333,2334,2334,2335,2336,2337,2338,2339,
	2340,2341,2341,2342,2343,2344,2345,2346,2347,2348,2348,2349,2350,2351,
	2352,2353,2354,2354,2355,2356,2357,2358,2359,2360,2361,2361,2362,2363,
	2364,2365,2366,2367,2368,2368,2369,2370,2371,2372,2373,2374,2374,
	2375,2376,2377,2378,2379,2380,2380,2381,2382,2383,2384,2385,2386,2386,
	2387,2388,2389,2390,2391,2392,2392,2393,2394,2395,2396,2397,2398,
	2398,2399,2400,2401,2402,2403,2404,2404,2405,2406,2407,2408,2409,2410,
	2410,2411,2412,2413,2414,2415,2415,2416,2417,2418,2419,2420,2421,2421,
	2422,2423,2424,2425,2426,2426,2427,2428,2429,2430,2431,2432,2432,
	2433,2434,2435,2436,2437,2437,2438,2439,2440,2441,2442,2442,2443,2444,
	2445,2446,2447,2447,2448,2449,2450,2451,2452,2452,2453,2454,2455,
	2456,2457,2457,2458,2459,2460,2461,2462,2462,2463,2464,2465,2466,2467,
	2467,2468,2469,2470,2471,2472,2472,2473,2474,2475,2476,2477,2477,2478,
	2479,2480,2481,2482,2482,2483,2484,2485,2486,2486,2487,2488,2489,
	2490,2491,2491,2492,2493,2494,2495,2496,2496,2497,2498,2499,2500,2500,
	2501,2502,2503,2504,2505,2505,2506,2507,2508,2509,2509,2510,2511,
	2512,2513,2513,2514,2515,2516,2517,2518,2518,2519,2520,2521,2522,2522,
	2523,2524,2525,2526,2526,2527,2528,2529,2530,2531,2531,2532,2533,2534,
	2535,2535,2536,2537,2538,2539,2539,2540,2541,2542,2543,2543,2544,
	2545,2546,2547,2547,2548,2549,2550,2551,2551,2552,2553,2554,2555,2555,
	2556,2557,2558,2559,2560,2560,2561,2562,2563,2563,2564,2565,2566,
	2567,2567,2568,2569,2570,2571,2571,2572,2573,2574,2575,2575,2576,2577,
	2578,2579,2579,2580,2581,2582,2583,2583,2584,2585,2586,2587,2587,2588,
	2589,2590,2591,2591,2592,2593,2594,2594,2595,2596,2597,2598,2598,
	2599,2600,2601,2602,2602,2603,2604,2605,2605,2606,2607,2608,2609,2609,
	2610,2611,2612,2613,2613,2614,2615,2616,2616,2617,2618,2619,2620,
	2620,2621,2622,2623,2624,2624,2625,2626,2627,2627,2628,2629,2630,2631,
	2631,2632,2633,2634,2634,2635,2636,2637,2638,2638,2639,2640,2641,2641,
	2642,2643,2644,2644,2645,2646,2647,2648,2648,2649,2650,2651,2651,
	2652,2653,2654,2655,2655,2656,2657,2658,2658,2659,2660,2661,2661,2662,
	2663,2664,2665,2665,2666,2667,2668,2668,2669,2670,2671,2671,2672,
	2673,2674,2675,2675,2676,2677,2678,2678,2679,2680,2681,2681,2682,2683,
	2684,2684,2685,2686,2687,2688,2688,2689,2690,2691,2691,2692,2693,2694,
	2694,2695,2696,2697,2697,2698,2699,2700,2700,2701,2702,2703,2703,
	2704,2705,2706,2706,2707,2708,2709,2710,2710,2711,2712,2713,2713,2714,
	2715,2716,2716,2717,2718,2719,2719,2720,2721,2722,2722,2723,2724,
	2725,2725,2726,2727,2728,2728,2729,2730,2731,2731,2732,2733,2734,2734,
	2735,2736,2737,2737,2738,2739,2740,2740,2741,2742,2743,2743,2744,2745,
	2746,2746,2747,2748,2749,2749,2750,2751,2752,2752,2753,2754,2754,
	2755,2756,2757,2757,2758,2759,2760,2760,2761,2762,2763,2763,2764,2765,
	2766,2766,2767,2768,2769,2769,2770,2771,2772,2772,2773,2774,2774,
	2775,2776,2777,2777,2778,2779,2780,2780,2781,2782,2783,2783,2784,2785,
	2786,2786,2787,2788,2788,2789,2790,2791,2791,2792,2793,2794,2794,2795,
	2796,2797,2797,2798,2799,2799,2800,2801,2802,2802,2803,2804,2805,
	2805,2806,2807,2807,2808,2809,2810,2810,2811,2812,2813,2813,2814,2815,
	2816,2816,2817,2818,2818,2819,2820,2821,2821,2822,2823,2823,2824,
	2825,2826,2826,2827,2828,2829,2829,2830,2831,2831,2832,2833,2834,2834,
	2835,2836,2837,2837,2838,2839,2839,2840,2841,2842,2842,2843,2844,2844,
	2845,2846,2847,2847,2848,2849,2849,2850,2851,2852,2852,2853,2854,
	2855,2855,2856,2857,2857,2858,2859,2860,2860,2861,2862,2862,2863,2864,
	2865,2865,2866,2867,2867,2868,2869,2870,2870,2871,2872,2872,2873,
	2874,2875,2875,2876,2877,2877,2878,2879,2880,2880,2881,2882,2882,2883,
	2884,2884,2885,2886,2887,2887,2888,2889,2889,2890,2891,2892,2892,2893,
	2894,2894,2895,2896,2897,2897,2898,2899,2899,2900,2901,2901,2902,
	2903,2904,2904,2905,2906,2906,2907,2908,2909,2909,2910,2911,2911,2912,
	2913,2913,2914,2915,2916,2916,2917,2918,2918,2919,2920,2920,2921,
	2922,2923,2923,2924,2925,2925,2926,2927,2927,2928,2929,2930,2930,2931,
	2932,2932,2933,2934,2934,2935,2936,2937,2937,2938,2939,2939,2940,2941,
	2941,2942,2943,2944,2944,2945,2946,2946,2947,2948,2948,2949,2950,
	2950,2951,2952,2953,2953,2954,2955,2955,2956,2957,2957,2958,2959,2959,
	2960,2961,2962,2962,2963,2964,2964,2965,2966,2966,2967,2968,2968,
	2969,2970,2971,2971,2972,2973,2973,2974,2975,2975,2976,2977,2977,2978,
	2979,2979,2980,2981,2982,2982,2983,2984,2984,2985,2986,2986,2987,2988,
	2988,2989,2990,2990,2991,2992,2992,2993,2994,2995,2995,2996,2997,
	2997,2998,2999,2999,3000,3001,3001,3002,3003,3003,3004,3005,3005,3006,
	3007,3008,3008,3009,3010,3010,3011,3012,3012,3013,3014,3014,3015,
	3016,3016,3017,3018,3018,3019,3020,3020,3021,3022,3022,3023,3024,3024,
	3025,3026,3027,3027,3028,3029,3029,3030,3031,3031,3032,3033,3033,3034,
	3035,3035,3036,3037,3037,3038,3039,3039,3040,3041,3041,3042,3043,
	3043,3044,3045,3045,3046,3047,3047,3048,3049,3049,3050,3051,3051,3052,
	3053,3053,3054,3055,3055,3056,3057,3057,3058,3059,3059,3060,3061,
	3061,3062,3063,3063,3064,3065,3065,3066,3067,3067,3068,3069,3069,3070,
	3071,3072,3072,3073,3073,3074,3075,3075,3076,3077,3077,3078,3079,3079,
	3080,3081,3081,3082,3083,3083,3084,3085,3085,3086,3087,3087,3088,
	3089,3089,3090,3091,3091,3092,3093,3093,3094,3095,3095,3096,3097,3097,
	3098,3099,3099,3100,3101,3101,3102,3103,3103,3104,3105,3105,3106,
	3107,3107,3108,3109,3109,3110,3111,3111,3112,3113,3113,3114,3115,3115,
	3116,3117,3117,3118,3118,3119,3120,3120,3121,3122,3122,3123,3124,3124,
	3125,3126,3126,3127,3128,3128,3129,3130,3130,3131,3132,3132,3133,
	3134,3134,3135,3136,3136,3137,3137,3138,3139,3139,3140,3141,3141,3142,
	3143,3143,3144,3145,3145,3146,3147,3147,3148,3149,3149,3150,3150,
	3151,3152,3152,3153,3154,3154,3155,3156,3156,3157,3158,3158,3159,3160,
	3160,3161,3162,3162,3163,3163,3164,3165,3165,3166,3167,3167,3168,3169,
	3169,3170,3171,3171,3172,3173,3173,3174,3174,3175,3176,3176,3177,
	3178,3178,3179,3180,3180,3181,3182,3182,3183,3183,3184,3185,3185,3186,
	3187,3187,3188,3189,3189,3190,3191,3191,3192,3192,3193,3194,3194,
	3195,3196,3196,3197,3198,3198,3199,3200,3200,3201,3201,3202,3203,3203,
	3204,3205,3205,3206,3207,3207,3208,3208,3209,3210,3210,3211,3212,3212,
	3213,3214,3214,3215,3215,3216,3217,3217,3218,3219,3219,3220,3221,
	3221,3222,3222,3223,3224,3224,3225,3226,3226,3227,3228,3228,3229,3229,
	3230,3231,3231,3232,3233,3233,3234,3235,3235,3236,3236,3237,3238,
	3238,3239,3240,3240,3241,3241,3242,3243,3243,3244,3245,3245,3246,3247,
	3247,3248,3248,3249,3250,3250,3251,3252,3252,3253,3253,3254,3255,3255,
	3256,3257,3257,3258,3258,3259,3260,3260,3261,3262,3262,3263,3264,
	3264,3265,3265,3266,3267,3267,3268,3269,3269,3270,3270,3271,3272,3272,
	3273,3274,3274,3275,3275,3276,3277,3277,3278,3279,3279,3280,3280,
	3281,3282,3282,3283,3284,3284,3285,3285,3286,3287,3287,3288,3289,3289,
	3290,3290,3291,3292,3292,3293,3293,3294,3295,3295,3296,3297,3297,3298,
	3298,3299,3300,3300,3301,3302,3302,3303,3303,3304,3305,3305,3306,
	3307,3307,3308,3308,3309,3310,3310,3311,3311,3312,3313,3313,3314,3315,
	3315,3316,3316,3317,3318,3318,3319,3319,3320,3321,3321,3322,3323,
	3323,3324,3324,3325,3326,3326,3327,3328,3328,3329,3329,3330,3331,3331,
	3332,3332,3333,3334,3334,3335,3335,3336,3337,3337,3338,3339,3339,3340,
	3340,3341,3342,3342,3343,3343,3344,3345,3345,3346,3347,3347,3348,
	3348,3349,3350,3350,3351,3351,3352,3353,3353,3354,3354,3355,3356,3356,
	3357,3358,3358,3359,3359,3360,3361,3361,3362,3362,3363,3364,3364,
	3365,3365,3366,3367,3367,3368,3368,3369,3370,3370,3371,3372,3372,3373,
	3373,3374,3375,3375,3376,3376,3377,3378,3378,3379,3379,3380,3381,3381,
	3382,3382,3383,3384,3384,3385,3385,3386,3387,3387,3388,3388,3389,
	3390,3390,3391,3392,3392,3393,3393,3394,3395,3395,3396,3396,3397,3398,
	3398,3399,3399,3400,3401,3401,3402,3402,3403,3404,3404,3405,3405,
	3406,3407,3407,3408,3408,3409,3410,3410,3411,3411,3412,3413,3413,3414,
	3414,3415,3416,3416,3417,3417,3418,3419,3419,3420,3420,3421,3422,3422,
	3423,3423,3424,3425,3425,3426,3426,3427,3428,3428,3429,3429,3430,
	3431,3431,3432,3432,3433,3434,3434,3435,3435,3436,3436,3437,3438,3438,
	3439,3439,3440,3441,3441,3442,3442,3443,3444,3444,3445,3445,3446,
	3447,3447,3448,3448,3449,3450,3450,3451,3451,3452,3453,3453,3454,3454,
	3455,3456,3456,3457,3457,3458,3458,3459,3460,3460,3461,3461,3462,3463,
	3463,3464,3464,3465,3466,3466,3467,3467,3468,3469,3469,3470,3470,
	3471,3471,3472,3473,3473,3474,3474,3475,3476,3476,3477,3477,3478,3479,
	3479,3480,3480,3481,3481,3482,3483,3483,3484,3484,3485,3486,3486,
	3487,3487,3488,3489,3489,3490,3490,3491,3491,3492,3493,3493,3494,3494,
	3495,3496,3496,3497,3497,3498,3498,3499,3500,3500,3501,3501,3502,3503,
	3503,3504,3504,3505,3506,3506,3507,3507,3508,3508,3509,3510,3510,
	3511,3511,3512,3513,3513,3514,3514,3515,3515,3516,3517,3517,3518,3518,
	3519,3520,3520,3521,3521,3522,3522,3523,3524,3524,3525,3525,3526,
	3526,3527,3528,3528,3529,3529,3530,3531,3531,3532,3532,3533,3533,3534,
	3535,3535,3536,3536,3537,3537,3538,3539,3539,3540,3540,3541,3542,3542,
	3543,3543,3544,3544,3545,3546,3546,3547,3547,3548,3548,3549,3550,
	3550,3551,3551,3552,3553,3553,3554,3554,3555,3555,3556,3557,3557,3558,
	3558,3559,3559,3560,3561,3561,3562,3562,3563,3563,3564,3565,3565,
	3566,3566,3567,3567,3568,3569,3569,3570,3570,3571,3571,3572,3573,3573,
	3574,3574,3575,3575,3576,3577,3577,3578,3578,3579,3579,3580,3581,3581,
	3582,3582,3583,3584,3584,3585,3585,3586,3586,3587,3587,3588,3589,
	3589,3590,3590,3591,3591,3592,3593,3593,3594,3594,3595,3595,3596,3597,
	3597,3598,3598,3599,3599,3600,3601,3601,3602,3602,3603,3603,3604,
	3605,3605,3606,3606,3607,3607,3608,3609,3609,3610,3610,3611,3611,3612,
	3613,3613,3614,3614,3615,3615,3616,3616,3617,3618,3618,3619,3619,3620,
	3620,3621,3622,3622,3623,3623,3624,3624,3625,3626,3626,3627,3627,
	3628,3628,3629,3629,3630,3631,3631,3632,3632,3633,3633,3634,3635,3635,
	3636,3636,3637,3637,3638,3639,3639,3640,3640,3641,3641,3642,3642,
	3643,3644,3644,3645,3645,3646,3646,3647,3648,3648,3649,3649,3650,3650,
	3651,3651,3652,3653,3653,3654,3654,3655,3655,3656,3656,3657,3658,3658,
	3659,3659,3660,3660,3661,3662,3662,3663,3663,3664,3664,3665,3665,
	3666,3667,3667,3668,3668,3669,3669,3670,3670,3671,3672,3672,3673,3673,
	3674,3674,3675,3675,3676,3677,3677,3678,3678,3679,3679,3680,3680,
	3681,3682,3682,3683,3683,3684,3684,3685,3685,3686,3687,3687,3688,3688,
	3689,3689,3690,3690,3691,3692,3692,3693,3693,3694,3694,3695,3695,3696,
	3697,3697,3698,3698,3699,3699,3700,3700,3701,3702,3702,3703,3703,
	3704,3704,3705,3705,3706,3707,3707,3708,3708,3709,3709,3710,3710,3711,
	3712,3712,3713,3713,3714,3714,3715,3715,3716,3716,3717,3718,3718,
	3719,3719,3720,3720,3721,3721,3722,3723,3723,3724,3724,3725,3725,3726,
	3726,3727,3727,3728,3729,3729,3730,3730,3731,3731,3732,3732,3733,3734,
	3734,3735,3735,3736,3736,3737,3737,3738,3738,3739,3740,3740,3741,
	3741,3742,3742,3743,3743,3744,3744,3745,3746,3746,3747,3747,3748,3748,
	3749,3749,3750,3750,3751,3752,3752,3753,3753,3754,3754,3755,3755,
	3756,3756,3757,3758,3758,3759,3759,3760,3760,3761,3761,3762,3762,3763,
	3764,3764,3765,3765,3766,3766,3767,3767,3768,3768,3769,3770,3770,3771,
	3771,3772,3772,3773,3773,3774,3774,3775,3776,3776,3777,3777,3778,
	3778,3779,3779,3780,3780,3781,3781,3782,3783,3783,3784,3784,3785,3785,
	3786,3786,3787,3787,3788,3788,3789,3790,3790,3791,3791,3792,3792,
	3793,3793,3794,3794,3795,3796,3796,3797,3797,3798,3798,3799,3799,3800,
	3800,3801,3801,3802,3803,3803,3804,3804,3805,3805,3806,3806,3807,3807,
	3808,3808,3809,3810,3810,3811,3811,3812,3812,3813,3813,3814,3814,
	3815,3815,3816,3816,3817,3818,3818,3819,3819,3820,3820,3821,3821,3822,
	3822,3823,3823,3824,3825,3825,3826,3826,3827,3827,3828,3828,3829,
	3829,3830,3830,3831,3831,3832,3833,3833,3834,3834,3835,3835,3836,3836,
	3837,3837,3838,3838,3839,3840,3840,3841,3841,3842,3842,3843,3843,3844,
	3844,3845,3845,3846,3846,3847,3847,3848,3849,3849,3850,3850,3851,
	3851,3852,3852,3853,3853,3854,3854,3855,3855,3856,3857,3857,3858,3858,
	3859,3859,3860,3860,3861,3861,3862,3862,3863,3863,3864,3864,3865,
	3866,3866,3867,3867,3868,3868,3869,3869,3870,3870,3871,3871,3872,3872,
	3873,3873,3874,3875,3875,3876,3876,3877,3877,3878,3878,3879,3879,3880,
	3880,3881,3881,3882,3882,3883,3884,3884,3885,3885,3886,3886,3887,
	3887,3888,3888,3889,3889,3890,3890,3891,3891,3892,3892,3893,3894,3894,
	3895,3895,3896,3896,3897,3897,3898,3898,3899,3899,3900,3900,3901,
	3901,3902,3902,3903,3904,3904,3905,3905,3906,3906,3907,3907,3908,3908,
	3909,3909,3910,3910,3911,3911,3912,3912,3913,3913,3914,3915,3915,3916,
	3916,3917,3917,3918,3918,3919,3919,3920,3920,3921,3921,3922,3922,
	3923,3923,3924,3924,3925,3925,3926,3927,3927,3928,3928,3929,3929,3930,
	3930,3931,3931,3932,3932,3933,3933,3934,3934,3935,3935,3936,3936,
	3937,3937,3938,3938,3939,3940,3940,3941,3941,3942,3942,3943,3943,3944,
	3944,3945,3945,3946,3946,3947,3947,3948,3948,3949,3949,3950,3950,3951,
	3951,3952,3953,3953,3954,3954,3955,3955,3956,3956,3957,3957,3958,
	3958,3959,3959,3960,3960,3961,3961,3962,3962,3963,3963,3964,3964,3965,
	3965,3966,3966,3967,3968,3968,3969,3969,3970,3970,3971,3971,3972,
	3972,3973,3973,3974,3974,3975,3975,3976,3976,3977,3977,3978,3978,3979,
	3979,3980,3980,3981,3981,3982,3982,3983,3983,3984,3984,3985,3986,3986,
	3987,3987,3988,3988,3989,3989,3990,3990,3991,3991,3992,3992,3993,
	3993,3994,3994,3995,3995,3996,3996,3997,3997,3998,3998,3999,3999,4000,
	4000,4001,4001,4002,4002,4003,4003,4004,4004,4005,4006,4006,4007,
	4007,4008,4008,4009,4009,4010,4010,4011,4011,4012,4012,4013,4013,4014,
	4014,4015,4015,4016,4016,4017,4017,4018,4018,4019,4019,4020,4020,4021,
	4021,4022,4022,4023,4023,4024,4024,4025,4025,4026,4026,4027,4027,
	4028,4028,4029,4029,4030,4030,4031,4032,4032,4033,4033,4034,4034,4035,
	4035,4036,4036,4037,4037,4038,4038,4039,4039,4040,4040,4041,4041,
	4042,4042,4043,4043,4044,4044,4045,4045,4046,4046,4047,4047,4048,4048,
	4049,4049,4050,4050,4051,4051,4052,4052,4053,4053,4054,4054,4055,4055,
	4056,4056,4057,4057,4058,4058,4059,4059,4060,4060,4061,4061,4062,
	4062,4063,4063,4064,4064,4065,4065,4066,4066,4067,4067,4068,4068,4069,
	4069,4070,4070,4071,4071,4072,4072,4073,4073,4074,4074,4075,4075,
	4076,4076,4077,4077,4078,4078,4079,4079,4080,4080,4081,4081,4082,4082,
	4083,4083,4084,4084,4085,4085,4086,4086,4087,4087,4088,4088,4089,4089,
	4090,4090,4091,4091,4092,4092,4093,4093,4094,4094,4095,
	};
/* USER CODE END Includes */

uint8_t LastSpiData = 0,SpiSeq = 0,MyAddress = 0x49,DataToRecieveLength=0;
uint8_t DataRX[20];
uint8_t NewDataFlag = 0;
uint32_t CommandRecieveCount = 0;
uint32_t DataLostCount = 0;
uint8_t  SpiRXData;
int16_t  InputSpeed = 0;
#define print(x) HAL_UART_Transmit(&huart1,(uint8_t *)x,strlen(x),100);
/* USER CODE BEGIN PV */
/* Private variables ---------------------------------------------------------*/

//ADC(CURRENT INPUT) :
	uint16_t ADC_DATA[3],ADC_FLT[3][8],FLT_CNT=0,I[3];//ADC raw and filtered data. these data contain 3 current sensors outputs.

//CURRENT_FEEDBACK :
	int32_t PHI_dq,Id,Iq;
	int32_t Ia,Ib,I1,I2,I3;//Alpha and Beta Currents and 3 sensors currents.
	int32_t I10=1638,I20=1638,I30=1638;//current sensors zero offset.these values represent the zero current.

//FREE_RUNNING :
	int32_t ACC=0,SPD=0,POS=0;//Acceleration,Speed,Position and current amplitude References.

//POLAR_CURRENT :
	int32_t PHI_IN,AMP_IN,AMP_OUT,PHI_OUT,ratio;//Phase and Amplitude of input current and output voltage.

//ANGLE_ESTIMATION :
	int32_t PHI_READ,T_MAX,DPHI,SPD_READ,ACC_READ,TIM2_OF,DELTA;

//HALL_SENSORS :
	int32_t const HALL_STATE[8]={6,3,1,2,5,4,0,6};
	int32_t const HALL_ANGLE[7]={4430,489,1224,2102,2812,3662,0};
//	int32_t const HALL_ANGLE[7]={4400,400,1200,2000,2800,3600,0};
	//1_3_2_6_4_5
	//2_3_1_5_4_6

//CONTROLLER :
	int32_t D_Id,D_Iq,I_Id,I_Iq,E_Id,E_Iq,R_Id,R_Iq;//Derivation,Integration,Error and Reference value of Alpha and Beta Currents.
	int32_t CTRL_d,CTRL_q,KP,KD,KI,INT_MAX;//Alpha-Beta Current control method PID Coefficients, controllers output and integrator maximum value.
	int32_t KFF,PI_Ratio;//Feed Forward Coefficient, KP to KI Ratio
	int32_t Ved,Veq,Ve_AMP,Ve_PHI;//Electromotive voltage (d,q),
	int32_t KMIX,Ve0,Ve1,K_RATE,KMIX_FLT[100];
//DEBUGING :
	int32_t EXTI_FLAG=0;

	int32_t DEBUG_1,DEBUG_2,DEBUG_3;

//Protection
	int32_t FAULT_CNT=0;//number of Faults

/* USER CODE END PV */

void SystemClock_Config(void);

/* USER CODE BEGIN PFP */
/* Private function prototypes -----------------------------------------------*/

	void ADC_FILTER()//Single Pole Digital Filter on ADC inputs
	{
		int i,j;
		for(j=0;j<3;j++){
			ADC_FLT[j][FLT_CNT]=ADC_DATA[j];
			I[j]=0;
			for(i=0;i<8;i++){
				I[j]+=ADC_FLT[j][i];
			}
			I[j]=I[j]>>3;
		}
		FLT_CNT++;
		if (FLT_CNT>=8)FLT_CNT=0;
	}

	void ab_CONV(int32_t *Ix,int32_t  *Iy)
	{
		I1=I[0]-1850;
		I2=I[1]-1850;
		I3=I[2]-1850;
		*Ix=(((I1-((I2+I3)>>1))*2730)>>12);
		*Iy=((I3-I2)*2364)>>12;
	}

	void dq_CONV(int32_t Ix,int32_t  Iy,int32_t PHI,int32_t *_Id,int32_t  *_Iq)
	{
		*_Id=Ix*COSINE_TABLE[PHI]>>11;
		*_Iq=Iy*COSINE_TABLE[PHI]>>11;
		PHI=1200-PHI;
		if(PHI<0)PHI+=4800;
		*_Id+=Iy*COSINE_TABLE[PHI]>>11;
		*_Iq-=Ix*COSINE_TABLE[PHI]>>11;
	}

	void POLAR_CONV(int32_t Ix,int32_t  Iy,int32_t *PHASE,int32_t *AMPLITUDE)
	{

		*AMPLITUDE=(Ix*Ix+Iy*Iy)>>10;
		if (*AMPLITUDE>=4096)*AMPLITUDE=4095;
		*AMPLITUDE=RADICAL[*AMPLITUDE];

		if (Ix>Iy)
		{
			if (Iy>-Ix)
			{
				ratio=((Iy<<11)/Ix)+2048;
				if (ratio>=4096)ratio=4095;
				if (ratio<0)ratio=0;
				*PHASE=INV_TAN[ratio];
			}else{
				ratio=((Ix<<11)/Iy)+2048;
				if (ratio>=4096)ratio=4095;
				if (ratio<0)ratio=0;
				*PHASE=-INV_TAN[ratio]+3600;
			}
		}else{
			if (Iy>-Ix)
			{
				ratio=2048-((Ix<<11)/Iy);
				if (ratio>=4096)ratio=4095;
				if (ratio<0)ratio=0;
				*PHASE=INV_TAN[ratio]+1200;
			}else{
				ratio=2048-((Iy<<11)/Ix);
				if (ratio>=4096)ratio=4095;
				if (ratio<0)ratio=0;
				*PHASE=-INV_TAN[ratio]+2400;
			}
		}
		if (*PHASE<0)*PHASE+=4800;
		if (*PHASE>=4800)*PHASE-=4800;
	}

	void SPWM(int32_t _PHASE,int32_t _AMPLITUDE)
	{
		if (_PHASE<0)_PHASE+=4800;
		if (_PHASE>=4800)_PHASE-=4800;
		TIM1->CCR1=((COSINE_TABLE[_PHASE]*_AMPLITUDE)>>12)+2048;

		_PHASE+=1600;
		if (_PHASE>=4800)_PHASE-=4800;
		TIM1->CCR2=((COSINE_TABLE[_PHASE]*_AMPLITUDE)>>12)+2048;

		_PHASE+=1600;
		if (_PHASE>=4800)_PHASE-=4800;
		TIM1->CCR3=((COSINE_TABLE[_PHASE]*_AMPLITUDE)>>12)+2048;
	}

	void SVM(int32_t _PHASE,int32_t _AMPLITUDE)
	{
		if (_PHASE<0)_PHASE+=4800;
		if (_PHASE>=4800)_PHASE-=4800;
		TIM1->CCR1=(SVM_TABLE[_PHASE]*_AMPLITUDE)>>13;

		_PHASE+=1600;
		if (_PHASE>=4800)_PHASE-=4800;
		TIM1->CCR2=(SVM_TABLE[_PHASE]*_AMPLITUDE)>>13;

		_PHASE+=1600;
		if (_PHASE>=4800)_PHASE-=4800;
		TIM1->CCR3=(SVM_TABLE[_PHASE]*_AMPLITUDE)>>13;
	}

	void PID_CTRL()
	{
	int32_t	t1,t2;
		t1=E_Id; //Last Error
		t2=E_Iq;
		E_Id=R_Id-Id; // New Error
		E_Iq=R_Iq-Iq;
		I_Id+=E_Id; // Error SUM
		I_Iq+=E_Iq;
		if (I_Id>=INT_MAX)I_Id=INT_MAX; // Clamp Integrated Error by +INT_MAX and -INT_MAX
		if (I_Id<-INT_MAX)I_Id=-INT_MAX;
		if (I_Iq>=INT_MAX)I_Iq=INT_MAX;
		if (I_Iq<-INT_MAX)I_Iq=-INT_MAX;
		D_Id=(((E_Id-t1)*1)+D_Id)>>1; // Single Pole Filtered Error Difference
		D_Iq=(((E_Iq-t2)*1)+D_Iq)>>1;
		CTRL_d=((E_Id*KP)>>12)+((I_Id*KI)>>12)+((D_Id*KD)>>12); // PID Controllers MIX
		if (CTRL_d>=2048)CTRL_d=2047; // Clamp Controller Output
		if (CTRL_d<-2048)CTRL_d=-2047;
		CTRL_q=((E_Iq*KP)>>12)+((I_Iq*KI)>>12)+((D_Iq*KD)>>12);
		if (CTRL_q>=2048)CTRL_q=2047;
		if (CTRL_q<=-2048)CTRL_q=-2047;
	}

	void CHC_CTRL()
	{
	int16_t	temp=0;
		if (Id>R_Id+20)temp=(R_Id>>1)-(AMP_IN>>2);
		if (Id<R_Id-20)temp=(R_Id>>1)+(AMP_IN>>2);
		CTRL_d=(CTRL_d*1+temp)>>1;
		if (CTRL_d>=2048)CTRL_d=2047;
		if (CTRL_d<-2048)CTRL_d=-2048;

		if (Iq>R_Iq+20)temp=(R_Iq>>1)-(AMP_IN>>2);
		if (Iq<R_Iq-20)temp=(R_Iq>>1)+(AMP_IN>>2);
		CTRL_q=(CTRL_q*1+temp)>>1;
		if (CTRL_q>=2048)CTRL_q=2047;
		if (CTRL_q<=-2048)CTRL_q=-2047;
	}

	void SPD_ESTIMATION()
	{
		DPHI=PHI_READ;
		PHI_READ=HALL_ANGLE[HALL_STATE[GPIOA->IDR&7]];
		DPHI=PHI_READ-DPHI;
		if (DPHI>2400)DPHI=4800-DPHI;
		if (DPHI<-2400)DPHI=4800+DPHI;
		ACC_READ=SPD_READ;
		SPD_READ=(DPHI*8000000)/T_MAX;
		ACC_READ=(ACC_READ-SPD_READ)*8/T_MAX;
	}

	void HAL_GPIO_EXTI_Callback(uint16_t GPIO_Pin)
	{
		EXTI_FLAG++;
		if ((TIM2->CNT>200)||(TIM2_OF)){
			T_MAX=TIM2->CNT;
			if (TIM2_OF)T_MAX=65535;
			TIM2_OF=0;
			SPD_ESTIMATION();
			TIM2->CNT=0;
		}
		EXTI_FLAG--;
	}

	void STATE_OBSERVER()
	{
		int32_t KMIX_nf;
		Ved=((Id*2867)>>12)-CTRL_d;
		Veq=((Iq*2867)>>12)-CTRL_q;
		POLAR_CONV(Ved,Veq,&Ve_PHI,&Ve_AMP);
		Ve_PHI+=PHI_dq+1200;
		while (Ve_PHI>=4800)Ve_PHI-=4800;
		if (Ve_AMP>Ve1)
		{
			KMIX_nf=4096;
		}else if (Ve_AMP>Ve0)
		{
			KMIX_nf=((Ve_AMP-Ve0)*K_RATE);
		}else{
			KMIX_nf=0;
		}
		KMIX=(KMIX*127+KMIX_nf)>>7;
		KMIX=4096;
	}

	void POSITION_ESTIMATOR()
	{
		if (((PHI_IN-Ve_PHI)<2400)&&((PHI_IN-Ve_PHI)>=-2400)){
			DEBUG_1=((PHI_IN*(4096-KMIX))+(Ve_PHI*KMIX))>>12;
		}else{
			if (PHI_IN<=2400){
				DEBUG_1=(((PHI_IN+4800)*(4096-KMIX))+(Ve_PHI*KMIX))>>12;
			}else{
				DEBUG_1=(((PHI_IN)*(4096-KMIX))+((Ve_PHI+4800)*KMIX))>>12;
			}
		}
		if (DEBUG_1>=4800)DEBUG_1-=4800;
		if (DEBUG_1<0)DEBUG_1+=4800;

		if (((DEBUG_2-DEBUG_1)<2400)&&((DEBUG_2-DEBUG_1)>=-2400)){
			DEBUG_2=(DEBUG_2*1023+DEBUG_1)>>10;
		}else{
			if (DEBUG_2<=2400){
				DEBUG_2=((DEBUG_2+4800)*1023+DEBUG_1)>>10;
			}else{
				DEBUG_2=(DEBUG_2*1023+(DEBUG_1+4800))>>10;
			}
		}
	}

	void SPEED_ESTIMATOR()
	{

	}

	void HAL_TIM_PeriodElapsedCallback(TIM_HandleTypeDef *htim)
	{
		if (htim==&htim4)
		{
			HAL_GPIO_WritePin(GPIOB,GPIO_PIN_1,0);
			HAL_GPIO_WritePin(GPIOB,GPIO_PIN_0,0);
			POS+=SPD;
			SPD+=ACC;
			if(SPD>=100000000)SPD=100000000;
			if(SPD<=-100000000)SPD=-100000000;
			while(POS>=10000000){
				POS-=10000000;
				PHI_IN++;
			}
			while(POS<=-10000000){
				POS+=10000000;
				PHI_IN--;
			}
			if(PHI_IN<0)PHI_IN+=4800;
			if(PHI_IN>=4800)PHI_IN-=4800;
			if (EXTI_FLAG!=0)
			{
				HAL_GPIO_WritePin(GPIOB,GPIO_PIN_1,0);
				SPD_ESTIMATION();
				EXTI_FLAG=0;
			}
			if (DPHI==0)
			{
				//FATAL ERROR
			}
			R_Id=0;
			R_Iq=AMP_IN;
			PHI_dq=PHI_IN;//Use this Line without Position Estimation
			POSITION_ESTIMATOR();
//			PHI_dq=DEBUG_1;
			ADC_FILTER();
			ab_CONV(&Ia,&Ib);
			dq_CONV(Ia,Ib,PHI_dq,&Id,&Iq);
			PID_CTRL();
//			CHC_CTRL();
			STATE_OBSERVER();
			POLAR_CONV(CTRL_d,CTRL_q,&PHI_OUT,&AMP_OUT);
//			POLAR_CONV(R_Id/3,R_Iq/3,&PHI_OUT,&AMP_OUT);
			PHI_OUT+=PHI_dq;
			if (PHI_OUT>=4800)PHI_OUT-=4800;
			DELTA=PHI_OUT-PHI_IN-1200;
			if (DELTA>=2400)DELTA-=4800;
			if (DELTA<-2400)DELTA+=4800;
			SPWM(PHI_OUT,AMP_OUT);
//			SVM(PHI_OUT,AMP_OUT);
			TIM3->CCR3=(Ve_AMP*256/4800);
			TIM3->CCR4=(DEBUG_1*256/4800);
			//current=26.8*(Vout-1.7)
//			if(HAL_GPIO_ReadPin(GPIOA,GPIO_PIN_0)==0)
//				HAL_GPIO_WritePin(GPIOB,GPIO_PIN_1,0);
//			else HAL_GPIO_WritePin(GPIOB,GPIO_PIN_1,1);
			//Hamed Codes {HJ}
			 if(NewDataFlag == 1 )
			 {
				  NewDataFlag = 0;
				  ProcessData();
			 }
			 //TODO : Uncomment next while for real test {HJ}
//			while(!(TIM1->BDTR&0x8000))
//			{
//				FAULT_CNT++;
//				HAL_Delay(50*FAULT_CNT*FAULT_CNT+100);
//				if (FAULT_CNT<5)TIM1->BDTR|=0x8000;
//			}
			HAL_GPIO_WritePin(GPIOB,GPIO_PIN_1,1);
			HAL_GPIO_WritePin(GPIOB,GPIO_PIN_0,1);

		}
		if (htim==&htim2)
		{
			TIM2_OF=1;
		}
	}

	void ZERO_INIT(void)
	{
		//CONTROLLER_PARAMETERS:
		PI_Ratio=30;
		KI=250;
		KP=PI_Ratio*KI;
		KD=20000;
		INT_MAX=(2048*4096)/KI;
		KMIX=0;
		Ve0=100;
		Ve1=1000;
		K_RATE=(4096/(Ve1-Ve0));
		PHI_dq=PHI_IN;
		//

		//FREE_RUNNING_PARAMETERS:
		AMP_IN=800;
		ACC=1000;
		SPD=10000000;
		//

		//CURRENT_SENSORS_OFFSET:
		I10=1860;
		I20=1860;
		I30=1860;
		//

		//ADC_INITIALIZE:
		HAL_ADCEx_Calibration_Start(&hadc1);//ADC calibration
		HAL_Delay(1000);//Waiting for Confidence.
		HAL_ADC_Start_DMA(&hadc1,(uint32_t *)ADC_DATA,3);//ADC START.
		//

		//TIMERS_INITIALIZE:
		TIM1->ARR=4096;//PWM GENERATOR TIMER : 17.578125 KHz
		TIM4->ARR=4800;//CONTROLL SYSTEM TIMER : 15 KHz
		TIM3->ARR=256;//DAC TIMER : 150KHz
		TIM2->ARR=601;//HALL Sensore Timer
		SVM(0,0);
		HAL_TIM_PWM_Start(&htim1,TIM_CHANNEL_1);
		HAL_TIM_PWM_Start(&htim1,TIM_CHANNEL_2);
		HAL_TIM_PWM_Start(&htim1,TIM_CHANNEL_3);
		HAL_TIMEx_PWMN_Start(&htim1,TIM_CHANNEL_1);
		HAL_TIMEx_PWMN_Start(&htim1,TIM_CHANNEL_2);
		HAL_TIMEx_PWMN_Start(&htim1,TIM_CHANNEL_3);

		HAL_TIM_PWM_Start(&htim3,TIM_CHANNEL_3);
		HAL_TIM_PWM_Start(&htim3,TIM_CHANNEL_4);

		HAL_GPIO_WritePin(GPIOA,GPIO_PIN_8|GPIO_PIN_9|GPIO_PIN_10,1);
		HAL_GPIO_WritePin(GPIOB,GPIO_PIN_13|GPIO_PIN_14|GPIO_PIN_15,1);

		HAL_TIM_Base_Start_IT(&htim4);
		HAL_TIM_Base_Start_IT(&htim2);
		//

		//INITIALIZATION_END:
		HAL_GPIO_WritePin(GPIOB,GPIO_PIN_1,1);
		HAL_GPIO_WritePin(GPIOB,GPIO_PIN_0,1);
		HAL_Delay(1000);
		HAL_GPIO_WritePin(GPIOB,GPIO_PIN_1,0);
		HAL_GPIO_WritePin(GPIOB,GPIO_PIN_0,0);
		HAL_Delay(1000);
		HAL_GPIO_WritePin(GPIOB,GPIO_PIN_1,1);
		HAL_GPIO_WritePin(GPIOB,GPIO_PIN_0,1);

		//
	}

/* USER CODE END PFP */

/* USER CODE BEGIN 0 */
	int ProcessData()
	{
		uint8_t tmp[20];
	 if(DataRX[0] == 0x01)
	 {
		 InputSpeed =(int16_t)(((DataRX[1]<<8) + DataRX[2])-10000);
		 sprintf(tmp,"SSC: Speed %d \r\n",InputSpeed);
		 //TODO : Remove next line after tests
		 print(tmp);
	 }
	 return 0;
	}
/* USER CODE END 0 */

int main(void)
{

  /* MCU Configuration----------------------------------------------------------*/

  /* Reset of all peripherals, Initializes the Flash interface and the Systick. */
  HAL_Init();

  /* Configure the system clock */
  SystemClock_Config();

  /* Initialize all configured peripherals */
  MX_GPIO_Init();
  MX_DMA_Init();
  MX_ADC1_Init();
  MX_SPI1_Init();
  MX_TIM1_Init();
  MX_TIM2_Init();
  MX_TIM3_Init();
  MX_TIM4_Init();
  MX_USART1_UART_Init();

  /* USER CODE BEGIN 2 */
  HAL_GPIO_WritePin(GPIOB,GPIO_PIN_0,GPIO_PIN_SET);
  HAL_GPIO_WritePin(GPIOB,GPIO_PIN_1,GPIO_PIN_SET);
  HAL_SPI_Receive_DMA(&hspi1,(uint8_t *)&SpiRXData,1);
  print("Driver Module Started.")
  	  ZERO_INIT();
  /* USER CODE END 2 */

  /* Infinite loop */
  while (1)
  {

  }

}

/** System Clock Configuration
*/
void SystemClock_Config(void)
{

  RCC_OscInitTypeDef RCC_OscInitStruct;
  RCC_ClkInitTypeDef RCC_ClkInitStruct;
  RCC_PeriphCLKInitTypeDef PeriphClkInit;

  RCC_OscInitStruct.OscillatorType = RCC_OSCILLATORTYPE_HSE;
  RCC_OscInitStruct.HSEState = RCC_HSE_ON;
  RCC_OscInitStruct.HSEPredivValue = RCC_HSE_PREDIV_DIV1;
  RCC_OscInitStruct.PLL.PLLState = RCC_PLL_ON;
  RCC_OscInitStruct.PLL.PLLSource = RCC_PLLSOURCE_HSE;
  RCC_OscInitStruct.PLL.PLLMUL = RCC_PLL_MUL6;
  HAL_RCC_OscConfig(&RCC_OscInitStruct);

  RCC_ClkInitStruct.ClockType = RCC_CLOCKTYPE_HCLK|RCC_CLOCKTYPE_SYSCLK
                              |RCC_CLOCKTYPE_PCLK1|RCC_CLOCKTYPE_PCLK2;
  RCC_ClkInitStruct.SYSCLKSource = RCC_SYSCLKSOURCE_PLLCLK;
  RCC_ClkInitStruct.AHBCLKDivider = RCC_SYSCLK_DIV1;
  RCC_ClkInitStruct.APB1CLKDivider = RCC_HCLK_DIV2;
  RCC_ClkInitStruct.APB2CLKDivider = RCC_HCLK_DIV1;
  HAL_RCC_ClockConfig(&RCC_ClkInitStruct, FLASH_LATENCY_2);

  PeriphClkInit.PeriphClockSelection = RCC_PERIPHCLK_ADC;
  PeriphClkInit.AdcClockSelection = RCC_ADCPCLK2_DIV6;
  HAL_RCCEx_PeriphCLKConfig(&PeriphClkInit);

  HAL_SYSTICK_Config(HAL_RCC_GetHCLKFreq()/1000);

  HAL_SYSTICK_CLKSourceConfig(SYSTICK_CLKSOURCE_HCLK);

  /* SysTick_IRQn interrupt configuration */
  HAL_NVIC_SetPriority(SysTick_IRQn, 0, 0);
}

/* USER CODE BEGIN 4 */
//{HJ}
void HAL_SPI_RxCpltCallback(SPI_HandleTypeDef *hspi){

	//DataLostCount++;
//	NewDataFlag = 1;
//	uint8_t temp[40];
//	sprintf(temp,"SDR:%#x\r\n",SpiRXData);
//
	//HAL_SPI_DMAPause(hspi);
	if(LastSpiData == 0xFF && SpiRXData == 0xFF)
	{
		//sprintf(temp,"Start Sequence Detected\r\n");
		SpiSeq=1; // Start Sequence Found
		NewDataFlag = 0;
	}
	else if( SpiSeq == 1 && LastSpiData == 0xFF)
	{
		if(SpiRXData == MyAddress)
		{
			SpiSeq = 2;
			//sprintf(temp,"Address Was OK\r\n");
		}
	}
	else if(SpiSeq == 2) //Length RX Sequence
	{
	  	   SpiSeq = 3;
	  	   DataToRecieveLength = SpiRXData;
	  	   //sprintf(temp,"Length Set to %d\r\n",SpiRXData);
	}
	else if(SpiSeq >= 3 && (SpiSeq-3 < DataToRecieveLength)) //Data Receiving
	{
		DataRX[SpiSeq-3] = SpiRXData;
		SpiSeq++;
		//sprintf(temp,"Receive %d number of data\r\n",SpiSeq-3);
	}
	else if(SpiSeq-3 == DataToRecieveLength)
	{
		uint8_t CheckSum = 0;
		//sprintf(temp,"End Sequence Detected\r\n");
		CheckSum = (uint8_t)((DataToRecieveLength + DataRX[0] + DataRX[1] + DataRX[2])&(0b11111111));
		if(CheckSum == SpiRXData)
		{
			CommandRecieveCount++;
			NewDataFlag = 1;
		}
    	else if (CheckSum != SpiRXData){
    		DataLostCount++;
    	}
		SpiSeq = 0;
	}
	//HAL_SPI_DMAResume(hspi);
	LastSpiData = SpiRXData;

}
//{HJ}
void HAL_SPI_ErrorCallback(SPI_HandleTypeDef *hspi)
{
	uint8_t temperr = 0;
	temperr = HAL_SPI_GetError(hspi);
	if (temperr == HAL_SPI_ERROR_NONE) {
		print("NoError\r\n");
	} else if (temperr == HAL_SPI_ERROR_MODF) {
		print("HAL_SPI_ERROR_MODF\r\n");
	} else if (temperr == HAL_SPI_ERROR_OVR) {
		print("HAL_SPI_ERROR_OVR\r\n");
	} else if (temperr == HAL_SPI_ERROR_OVR) {
		print("HAL_SPI_ERROR_DMA\r\n");
	} else if (temperr == HAL_SPI_ERROR_OVR) {
		print("HAL_SPI_ERROR_FLAG\r\n");
	}

	hspi->ErrorCode =  HAL_SPI_ERROR_NONE;
	HAL_SPI_Receive_DMA(&hspi1,(uint8_t *)&SpiRXData,1);
}
/* USER CODE END 4 */

/************************ (C) COPYRIGHT STMicroelectronics *****END OF FILE****/
